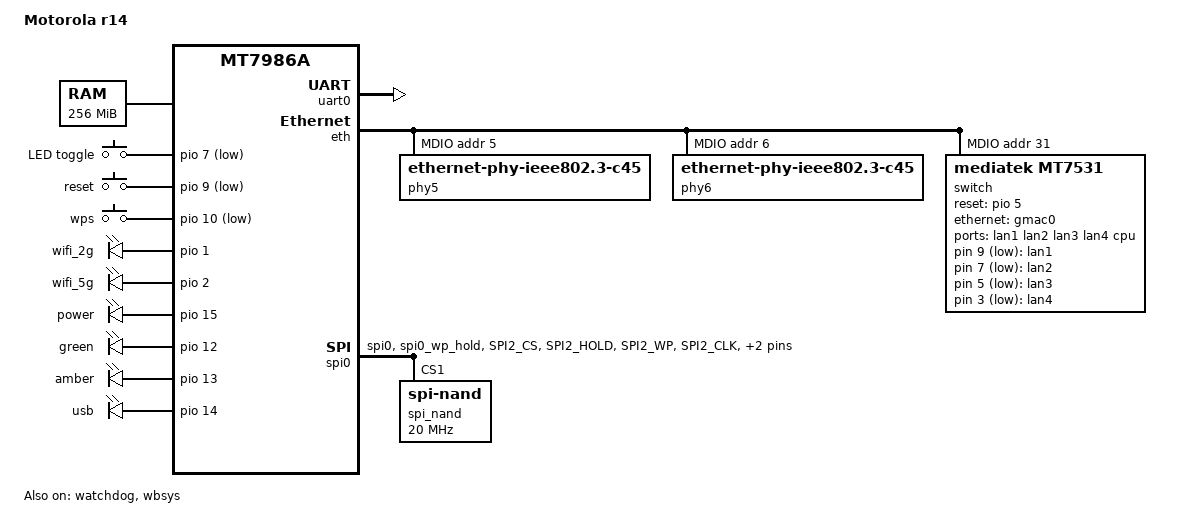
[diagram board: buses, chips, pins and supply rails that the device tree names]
/dts-v1/;
#include "mt7986a.dtsi"
#include "mt7986a-pinctrl.dtsi"
#include <dt-bindings/gpio/gpio.h>
#include <dt-bindings/input/linux-event-codes.h>
/ {
	model = "Motorola r14";
	compatible = "motorola,r14";

	chosen {
		bootargs = "console=ttyS0,115200n1 loglevel=8  \
				earlycon=uart8250,mmio32,0x11002000";
	};

	memory {
		reg = <0 0x40000000 0 0x10000000>;
	};

	gpio-keys {
		compatible = "gpio-keys";

		led_toggle {
			label = "LED toggle";
			linux,code = <KEY_LIGHTS_TOGGLE>;
			gpios = <&pio 7 GPIO_ACTIVE_LOW>;			
		};

		reset {
			label = "reset";
			linux,code = <KEY_RESTART>;
			gpios = <&pio 9 GPIO_ACTIVE_LOW>;			
		};

		wps {
			label = "wps";
			linux,code = <KEY_WPS_BUTTON>;
			gpios = <&pio 10 GPIO_ACTIVE_LOW>;
		};
	};

	leds {
		compatible = "gpio-leds";

		wifi_2g {
			label = "wifi_2g";
			gpios = <&pio 1 GPIO_ACTIVE_HIGH>;
			default-state = "off";
		};

		wifi_5g {
			label = "wifi_5g";
			gpios = <&pio 2 GPIO_ACTIVE_HIGH>;
			default-state = "off";
		};

		power {
			label = "power";
			gpios = <&pio 15 GPIO_ACTIVE_HIGH>;
			default-state = "on";
		};

		green {
			label = "green";
			gpios = <&pio 12 GPIO_ACTIVE_HIGH>;
			default-state = "off";
		};

		amber {
			label = "amber";
			gpios = <&pio 13 GPIO_ACTIVE_HIGH>;
			default-state = "off";
		};

		usb {
			label = "usb";
			gpios = <&pio 14 GPIO_ACTIVE_HIGH>;
			default-state = "off";
		};

		lan1 {
			label = "lan1";
			gpios = <&switch 9 GPIO_ACTIVE_LOW>;
			default-state = "off";
		};

		lan2 {
			label = "lan2";
			gpios = <&switch 7 GPIO_ACTIVE_LOW>;
			default-state = "off";
		};

		lan3 {
			label = "lan3";
			gpios = <&switch 5 GPIO_ACTIVE_LOW>;
			default-state = "off";
		};

		lan4 {
			label = "lan4";
			gpios = <&switch 3 GPIO_ACTIVE_LOW>;
			default-state = "off";
		};
        };


	nmbm_spim_nand {
		compatible = "generic,nmbm";

		#address-cells = <1>;
		#size-cells = <1>;

		lower-mtd-device = <&spi_nand>;
		forced-create;

		partitions {
			compatible = "fixed-partitions";
			#address-cells = <1>;
			#size-cells = <1>;

			partition@0 {
				label = "BL2";
				reg = <0x00000 0x0100000>;
				read-only;
			};

			partition@100000 {
				label = "u-boot-env";
				reg = <0x0100000 0x0060000>;
			};

			partition@160000 {
				label = "certificates";
				reg = <0x0160000 0x0020000>;
			};

			factory: partition@180000 {
				label = "Factory";
				reg = <0x180000 0x0200000>;
			};

			partition@380000 {
				label = "FIP";
				reg = <0x380000 0x0200000>;
			};

			partition@580000 {
				label = "ubi";
				reg = <0x580000 0x4000000>;
			};
		};
	};
};

&uart0 {
	status = "okay";
};

&watchdog {
	status = "okay";
};

&eth {
	status = "okay";

	gmac0: mac@0 {
		compatible = "mediatek,eth-mac";
		reg = <0>;
		phy-mode = "2500base-x";

		fixed-link {
			speed = <2500>;
			full-duplex;
			pause;
		};
	};

	gmac1: mac@1 {
		compatible = "mediatek,eth-mac";
		reg = <1>;
		phy-mode = "2500base-x";
		phy-handle = <&phy6>;
	};

	mdio: mdio-bus {
		#address-cells = <1>;
		#size-cells = <0>;

		reset-gpios = <&pio 6 1>;
		reset-delay-us = <600>;

		phy5: phy@5 {
			compatible = "ethernet-phy-ieee802.3-c45";
			reg = <5>;
		};

		phy6: phy@6 {
			compatible = "ethernet-phy-ieee802.3-c45";
			reg = <6>;
		};

		switch: switch@0 {
			compatible = "mediatek,mt7531";
			gpio-controller;
			#gpio-cells = <2>;
			reg = <31>;
			reset-gpios = <&pio 5 0>;

			ports {
				#address-cells = <1>;
				#size-cells = <0>;

				port@1 {
					reg = <1>;
					label = "lan1";
				};

				port@2 {
					reg = <2>;
					label = "lan2";
				};

				port@3 {
					reg = <3>;
					label = "lan3";
				};

				port@4 {
					reg = <4>;
					label = "lan4";
				};

				port@6 {
					reg = <6>;
					label = "cpu";
					ethernet = <&gmac0>;
					phy-mode = "2500base-x";

					fixed-link {
						speed = <2500>;
						full-duplex;
						pause;
					};
				};
			};
		};
	};
};

&spi0 {
	pinctrl-names = "default";
	pinctrl-0 = <&spi_flash_pins>;
	cs-gpios = <0>, <0>;
	status = "okay";

	spi_nand: spi_nand@1 {
		#address-cells = <1>;
		#size-cells = <1>;
		compatible = "spi-nand";
		reg = <1>;
		spi-max-frequency = <20000000>;
		spi-tx-buswidth = <4>;
		spi-rx-buswidth = <4>;
	};
};

&wbsys {
	mediatek,mtd-eeprom = <&factory 0x0000>;
	status = "okay";
	pinctrl-names = "default", "dbdc";
	pinctrl-0 = <&wf_2g_5g_pins>;
	pinctrl-1 = <&wf_dbdc_pins>;
	power-limits {
		r0 {
			country = "US";
			txpower-2g {
				r0 {
					channels = <1 1>;
					rates-cck = <39 39 39 39>;
					rates-ofdm = <37 37 37 37 37 37 37 37>;
					rates-mcs =
						<1 35 35 35 35 35 35 35 35 35 35>,
						<1 28 28 28 28 28 28 28 28 28 28>,
						<1 30 31 32 30 20 33 25 23 39 34>,
						<1 24 26 36 28 31 33 23 33 21 25>;
					rates-ru =
						<4 35 35 35 35 35 35 35 35 35 35 42 35>,
						<3 28 28 28 28 28 28 28 28 28 28 28 28>;
					paths-cck = <51 45 42 39>;
					paths-ofdm = <49 43 40 37>;
					paths-ofdm-bf = <0 43 40 37>;
					paths-ru =
						<1 47 41 38 35 41 38 35 38 35 35>,
						<1 40 34 31 28 34 31 28 31 28 28>,
						<1 27 38 20 26 28 20 29 21 36 30>,
						<1 35 39 24 31 25 30 25 29 27 39>,
						<3 47 41 38 35 41 38 35 38 35 35>;
					paths-ru-bf =
						<1 0 41 38 35 43 39 37 41 37 39>,
						<1 0 34 31 28 36 32 30 34 30 32>,
						<1 0 30 23 39 28 21 25 29 28 21>,
						<1 0 34 20 38 32 35 33 37 26 36>,
						<3 47 41 38 35 43 39 37 41 37 39>;
				};
				r1 {
					channels = <2 2>;
					rates-cck = <40 40 40 40>;
					rates-ofdm = <38 38 38 38 38 38 38 38>;
					rates-mcs =
						<1 37 37 37 37 37 37 37 37 37 37>,
						<1 28 28 28 28 28 28 28 28 28 28>,
						<1 30 31 32 30 20 33 25 23 39 34>,
						<1 24 26 36 28 31 33 23 33 21 25>;
					rates-ru =
						<4 37 37 37 37 37 37 37 37 37 37 37 37>,
						<3 28 28 28 28 28 28 28 28 28 28 28 28>;
					paths-cck = <52 46 43 40>;
					paths-ofdm = <50 44 41 38>;
					paths-ofdm-bf = <0 44 41 38>;
					paths-ru =
						<1 49 43 40 37 43 40 37 40 37 37>,
						<1 40 34 31 28 34 31 28 31 28 28>,
						<1 35 34 39 30 24 33 23 23 36 34>,
						<1 37 33 31 20 33 38 29 33 39 37>,
						<3 49 43 40 37 43 40 37 40 37 37>;
					paths-ru-bf =
						<1 0 43 40 37 45 41 39 43 39 41>,
						<1 0 34 31 28 36 32 30 34 30 32>,
						<1 0 29 21 24 33 24 30 22 22 31>,
						<1 0 38 34 33 23 25 39 30 31 32>,
						<3 49 43 40 37 45 41 39 43 39 41>;
				};
				r2 {
					channels = <3 3>;
					rates-cck = <43 43 43 43>;
					rates-ofdm = <40 40 40 40 40 40 40 40>;
					rates-mcs =
						<1 40 40 40 40 40 40 40 40 40 40>,
						<1 28 28 28 28 28 28 28 28 28 28>,
						<1 38 24 33 22 26 36 31 23 39 33>,
						<1 33 34 34 35 22 28 21 35 35 33>;
					rates-ru =
						<4 40 40 40 40 40 40 40 40 40 40 42 40>,
						<3 28 28 28 28 28 28 28 28 28 28 28 28>;
					paths-cck = <55 49 46 43>;
					paths-ofdm = <52 46 43 40>;
					paths-ofdm-bf = <0 46 43 40>;
					paths-ru =
						<1 52 46 43 40 46 43 40 43 40 40>,
						<1 40 34 31 28 34 31 28 31 28 28>,
						<1 30 38 34 37 35 31 39 20 26 23>,
						<1 33 25 35 25 32 27 35 22 29 35>,
						<3 52 46 43 40 46 43 40 43 40 40>;
					paths-ru-bf =
						<1 0 46 43 40 48 44 42 46 42 44>,
						<1 0 34 31 28 36 32 30 34 30 32>,
						<1 0 33 35 25 33 35 25 29 21 37>,
						<1 0 37 35 26 25 26 30 27 35 34>,
						<3 52 46 43 40 48 44 42 46 42 44>;
				};
				r3 {
					channels = <4 4>;
					rates-cck = <43 43 43 43>;
					rates-ofdm = <40 40 40 40 40 40 40 40>;
					rates-mcs =
						<1 40 40 40 40 40 40 40 40 40 40>,
						<1 32 32 32 32 32 32 32 32 32 32>,
						<1 38 23 25 21 27 38 20 23 39 36>,
						<1 23 24 20 26 37 31 29 30 22 36>;
					rates-ru =
						<4 40 40 40 40 40 40 40 40 40 40 42 40>,
						<3 32 32 32 32 32 32 32 32 32 32 32 32>;
					paths-cck = <55 49 46 43>;
					paths-ofdm = <52 46 43 40>;
					paths-ofdm-bf = <0 46 43 40>;
					paths-ru =
						<1 52 46 43 40 46 43 40 43 40 40>,
						<1 44 38 35 32 38 35 32 35 32 32>,
						<1 30 36 23 20 21 20 28 28 26 24>,
						<1 29 26 22 28 21 24 26 21 38 22>,
						<3 52 46 43 40 46 43 40 43 40 40>;
					paths-ru-bf =
						<1 0 46 43 40 48 44 42 46 42 44>,
						<1 0 38 35 32 40 36 34 38 34 36>,
						<1 0 28 37 30 26 20 38 35 21 27>,
						<1 0 39 39 32 25 26 33 32 33 25>,
						<3 52 46 43 40 48 44 42 46 42 44>;
				};
				r4 {
					channels = <5 5>;
					rates-cck = <43 43 43 43>;
					rates-ofdm = <40 40 40 40 40 40 40 40>;
					rates-mcs =
						<1 40 40 40 40 40 40 40 40 40 40>,
						<1 36 36 36 36 36 36 36 36 36 36>,
						<1 21 37 28 38 39 35 30 29 36 24>,
						<1 30 22 37 34 37 32 34 27 27 31>;
					rates-ru =
						<4 40 40 40 40 40 40 40 40 40 40 42 40>,
						<3 36 36 36 36 36 36 36 36 36 36 36 36>;
					paths-cck = <55 49 46 43>;
					paths-ofdm = <52 46 43 40>;
					paths-ofdm-bf = <0 46 43 40>;
					paths-ru =
						<1 52 46 43 40 46 43 40 43 40 40>,
						<1 48 42 39 36 42 39 36 39 36 36>,
						<1 25 31 23 25 27 25 26 28 25 34>,
						<1 29 38 27 22 37 25 33 35 34 31>,
						<3 52 46 43 40 46 43 40 43 40 40>;
					paths-ru-bf =
						<1 0 46 43 40 48 44 42 46 42 44>,
						<1 0 42 39 36 44 40 38 42 38 40>,
						<1 0 37 29 36 27 25 25 28 30 31>,
						<1 0 23 26 34 34 37 37 23 23 38>,
						<3 52 46 43 40 48 44 42 46 42 44>;
				};
				r5 {
					channels = <6 6>;
					rates-cck = <43 43 43 43>;
					rates-ofdm = <40 40 40 40 40 40 40 40>;
					rates-mcs =
						<1 40 40 40 40 40 40 40 40 40 40>,
						<1 36 36 36 36 36 36 36 36 36 36>,
						<1 33 39 30 36 33 37 38 39 38 35>,
						<1 29 23 22 36 23 21 28 35 36 33>;
					rates-ru =
						<4 40 40 40 40 40 40 40 40 40 40 42 40>,
						<3 36 36 36 36 36 36 36 36 36 36 36 36>;
					paths-cck = <55 49 46 43>;
					paths-ofdm = <52 46 43 40>;
					paths-ofdm-bf = <0 46 43 40>;
					paths-ru =
						<1 52 46 43 40 46 43 40 43 40 40>,
						<1 48 42 39 36 42 39 36 39 36 36>,
						<1 39 28 27 38 36 28 38 23 25 30>,
						<1 30 37 27 24 34 33 39 29 29 24>,
						<3 52 46 43 40 46 43 40 43 40 40>;
					paths-ru-bf =
						<1 0 46 43 40 48 44 42 46 42 44>,
						<1 0 42 39 36 44 40 38 42 38 40>,
						<1 0 33 24 27 27 36 22 26 27 38>,
						<1 0 20 30 32 26 39 36 28 38 34>,
						<3 52 46 43 40 48 44 42 46 42 44>;
				};
				r6 {
					channels = <7 7>;
					rates-cck = <43 43 43 43>;
					rates-ofdm = <40 40 40 40 40 40 40 40>;
					rates-mcs =
						<1 40 40 40 40 40 40 40 40 40 40>,
						<1 36 36 36 36 36 36 36 36 36 36>,
						<1 22 29 34 29 20 28 37 32 28 38>,
						<1 31 23 31 36 25 21 23 23 23 36>;
					rates-ru =
						<4 40 40 40 40 40 40 40 40 40 40 42 40>,
						<3 36 36 36 36 36 36 36 36 36 36 36 36>;
					paths-cck = <55 49 46 43>;
					paths-ofdm = <52 46 43 40>;
					paths-ofdm-bf = <0 46 43 40>;
					paths-ru =
						<1 52 46 43 40 46 43 40 43 40 40>,
						<1 48 42 39 36 42 39 36 39 36 36>,
						<1 24 26 29 29 32 34 26 29 21 37>,
						<1 27 33 25 22 35 20 37 32 30 37>,
						<3 52 46 43 40 46 43 40 43 40 40>;
					paths-ru-bf =
						<1 0 46 43 40 48 44 42 46 42 44>,
						<1 0 42 39 36 44 40 38 42 38 40>,
						<1 0 26 24 27 31 28 22 31 23 32>,
						<1 0 21 33 37 38 34 25 36 39 27>,
						<3 52 46 43 40 48 44 42 46 42 44>;
				};
				r7 {
					channels = <8 8>;
					rates-cck = <43 43 43 43>;
					rates-ofdm = <40 40 40 40 40 40 40 40>;
					rates-mcs =
						<1 40 40 40 40 40 40 40 40 40 40>,
						<1 31 31 31 31 31 31 31 31 31 31>,
						<1 27 20 34 28 20 20 30 36 31 35>,
						<1 37 20 34 38 35 28 20 32 21 25>;
					rates-ru =
						<4 40 40 40 40 40 40 40 40 40 40 42 40>,
						<3 31 31 31 31 31 31 31 31 31 31 31 31>;
					paths-cck = <55 49 46 43>;
					paths-ofdm = <52 46 43 40>;
					paths-ofdm-bf = <0 46 43 40>;
					paths-ru =
						<1 52 46 43 40 46 43 40 43 40 40>,
						<1 43 37 34 31 37 34 31 34 31 31>,
						<1 32 29 31 34 25 30 25 26 36 31>,
						<1 21 33 36 36 36 32 27 31 38 26>,
						<3 52 46 43 40 46 43 40 43 40 40>;
					paths-ru-bf =
						<1 0 46 43 40 48 44 42 46 42 44>,
						<1 0 37 34 31 39 35 33 37 33 35>,
						<1 0 24 29 21 27 21 25 39 35 21>,
						<1 0 36 38 38 32 30 32 39 28 34>,
						<3 52 46 43 40 48 44 42 46 42 44>;
				};
				r8 {
					channels = <9 9>;
					rates-cck = <43 43 43 43>;
					rates-ofdm = <40 40 40 40 40 40 40 40>;
					rates-mcs =
						<1 40 40 40 40 40 40 40 40 40 40>,
						<1 30 30 30 30 30 30 30 30 30 30>,
						<1 25 25 27 35 32 35 20 30 32 37>,
						<1 36 34 38 30 35 39 36 33 20 25>;
					rates-ru =
						<4 40 40 40 40 40 40 40 40 40 40 42 40>,
						<3 30 30 30 30 30 30 30 30 30 30 30 30>;
					paths-cck = <55 49 46 43>;
					paths-ofdm = <52 46 43 40>;
					paths-ofdm-bf = <0 46 43 40>;
					paths-ru =
						<1 52 46 43 40 46 43 40 43 40 40>,
						<1 42 36 33 30 36 33 30 33 30 30>,
						<1 24 27 27 22 25 33 24 32 23 21>,
						<1 33 22 27 35 34 30 21 25 20 35>,
						<3 52 46 43 40 46 43 40 43 40 40>;
					paths-ru-bf =
						<1 0 46 43 40 48 44 42 46 42 44>,
						<1 0 36 33 30 38 34 32 36 32 34>,
						<1 0 24 25 31 20 30 28 34 29 22>,
						<1 0 30 22 26 33 29 37 39 32 37>,
						<3 52 46 43 40 48 44 42 46 42 44>;
				};
				r9 {
					channels = <10 10>;
					rates-cck = <43 43 43 43>;
					rates-ofdm = <40 40 40 40 40 40 40 40>;
					rates-mcs =
						<1 40 40 40 40 40 40 40 40 40 40>,
						<1 30 30 30 30 30 30 30 30 30 30>,
						<1 31 39 34 29 38 29 38 35 24 20>,
						<1 36 34 25 32 32 28 39 25 35 24>;
					rates-ru =
						<4 40 40 40 40 40 40 40 40 40 40 42 40>,
						<3 30 30 30 30 30 30 30 30 30 30 30 30>;
					paths-cck = <55 49 46 43>;
					paths-ofdm = <52 46 43 40>;
					paths-ofdm-bf = <0 46 43 40>;
					paths-ru =
						<1 52 46 43 40 46 43 40 43 40 40>,
						<1 42 36 33 30 36 33 30 33 30 30>,
						<1 27 21 34 30 22 38 30 22 32 38>,
						<1 30 33 34 33 32 24 39 28 39 35>,
						<3 52 46 43 40 46 43 40 43 40 40>;
					paths-ru-bf =
						<1 0 46 43 40 48 44 42 46 42 44>,
						<1 0 36 33 30 38 34 32 36 32 34>,
						<1 0 35 30 38 21 38 23 21 35 28>,
						<1 0 36 35 21 30 38 23 32 33 31>,
						<3 52 46 43 40 48 44 42 46 42 44>;
				};
				r10 {
					channels = <11 11>;
					rates-cck = <37 37 37 37>;
					rates-ofdm = <36 36 36 36 36 36 36 36>;
					rates-mcs =
						<1 36 36 36 36 36 36 36 36 36 36>,
						<1 30 30 30 30 30 30 30 30 30 30>,
						<1 23 26 33 31 26 21 38 34 39 20>,
						<1 29 30 22 31 34 33 28 34 24 20>;
					rates-ru =
						<4 36 36 36 36 36 36 36 36 36 36 42 36>,
						<3 30 30 30 30 30 30 30 30 30 30 30 30>;
					paths-cck = <49 43 40 37>;
					paths-ofdm = <48 42 39 36>;
					paths-ofdm-bf = <0 42 39 36>;
					paths-ru =
						<1 48 42 39 36 42 39 36 39 36 36>,
						<1 42 36 33 30 36 33 30 33 30 30>,
						<1 26 38 39 25 37 26 32 38 36 24>,
						<1 23 36 27 26 29 36 28 31 36 37>,
						<3 48 42 39 36 42 39 36 39 36 36>;
					paths-ru-bf =
						<1 0 42 39 36 44 40 38 42 38 40>,
						<1 0 36 33 30 38 34 32 36 32 34>,
						<1 0 35 23 38 35 37 27 37 26 22>,
						<1 0 24 25 36 38 30 20 27 22 29>,
						<3 48 42 39 36 44 40 38 42 38 40>;
				};
				r11 {
					channels = <12 12>;
					rates-cck = <37 37 37 37>;
					rates-ofdm = <36 36 36 36 36 36 36 36>;
					rates-mcs =
						<1 36 36 36 36 36 36 36 36 36 36>,
						<1 30 30 30 30 30 30 30 30 30 30>,
						<1 20 36 37 24 24 29 34 27 31 24>,
						<1 29 22 21 38 24 25 31 23 20 21>;
					rates-ru =
						<4 36 36 36 36 36 36 36 36 36 36 42 36>,
						<3 30 30 30 30 30 30 30 30 30 30 30 30>;
					paths-cck = <49 43 40 37>;
					paths-ofdm = <48 42 39 36>;
					paths-ofdm-bf = <0 42 39 36>;
					paths-ru =
						<1 48 42 39 36 42 39 36 39 36 36>,
						<1 42 36 33 30 36 33 30 33 30 30>,
						<1 25 23 35 29 35 20 23 39 36 24>,
						<1 34 21 30 34 24 24 24 32 23 31>,
						<3 48 42 39 36 42 39 36 39 36 36>;
					paths-ru-bf =
						<1 0 42 39 36 44 40 38 42 38 40>,
						<1 0 36 33 30 38 34 32 36 32 34>,
						<1 0 25 25 20 21 25 29 37 29 22>,
						<1 0 29 37 25 37 35 31 30 39 39>,
						<3 48 42 39 36 44 40 38 42 38 40>;
				};
				r12 {
					channels = <13 13>;
					rates-cck = <37 37 37 37>;
					rates-ofdm = <36 36 36 36 36 36 36 36>;
					rates-mcs =
						<1 36 36 36 36 36 36 36 36 36 36>,
						<1 30 30 30 30 30 30 30 30 30 30>,
						<1 29 24 37 23 38 36 39 32 35 33>,
						<1 21 26 33 29 27 28 34 36 23 32>;
					rates-ru =
						<4 36 36 36 36 36 36 36 36 36 36 42 36>,
						<3 30 30 30 30 30 30 30 30 30 30 30 30>;
					paths-cck = <49 43 40 37>;
					paths-ofdm = <48 42 39 36>;
					paths-ofdm-bf = <0 42 39 36>;
					paths-ru =
						<1 48 42 39 36 42 39 36 39 36 36>,
						<1 42 36 33 30 36 33 30 33 30 30>,
						<1 28 23 27 25 39 20 23 27 36 30>,
						<1 25 23 34 26 37 26 32 37 36 31>,
						<3 48 42 39 36 42 39 36 39 36 36>;
					paths-ru-bf =
						<1 0 42 39 36 44 40 38 42 38 40>,
						<1 0 36 33 30 38 34 32 36 32 34>,
						<1 0 31 32 31 34 33 27 36 22 20>,
						<1 0 32 25 23 39 20 28 37 21 32>,
						<3 48 42 39 36 44 40 38 42 38 40>;
				};
				r13 {
					channels = <14 14>;
					rates-cck = <37 37 37 37>;
					rates-ofdm = <36 36 36 36 36 36 36 36>;
					rates-mcs =
						<1 36 36 36 36 36 36 36 36 36 36>,
						<1 30 30 30 30 30 30 30 30 30 30>,
						<1 38 29 37 27 28 24 32 37 33 22>,
						<1 31 37 23 28 23 35 21 22 20 34>;
					rates-ru =
						<4 36 36 36 36 36 36 36 36 36 36 42 36>,
						<3 30 30 30 30 30 30 30 30 30 30 30 30>;
					paths-cck = <49 43 40 37>;
					paths-ofdm = <48 42 39 36>;
					paths-ofdm-bf = <0 42 39 36>;
					paths-ru =
						<1 48 42 39 36 42 39 36 39 36 36>,
						<1 42 36 33 30 36 33 30 33 30 30>,
						<1 26 36 26 37 26 20 36 21 30 30>,
						<1 24 33 33 27 25 27 29 39 37 30>,
						<3 48 42 39 36 42 39 36 39 36 36>;
					paths-ru-bf =
						<1 0 42 39 36 44 40 38 42 38 40>,
						<1 0 36 33 30 38 34 32 36 32 34>,
						<1 0 36 24 22 27 32 29 36 36 37>,
						<1 0 33 29 29 36 32 29 36 25 39>,
						<3 48 42 39 36 44 40 38 42 38 40>;
				};
			};
			txpower-5g {
				r0 {
					channels =
						<1 1>,
						<61 61>,
						<121 121>,
						<181 181>;
					rates-cck = <22 26 24 30>;
					rates-ofdm = <24 26 28 32 36 22 24 22>;
					rates-mcs = <4 24 26 28 32 36 22 24 22 26 28>;
					rates-ru =
						<4 24 26 28 32 36 22 24 22 26 28 32 36>,
						<1 22 24 26 28 30 32 34 36 38 24 30 26>,
						<1 26 30 24 38 36 34 32 30 28 26 24 22>,
						<1 20 22 24 30 36 22 32 34 22 24 26 28>;
					paths-cck = <30 24 34 21>;
					paths-ofdm = <20 26 24 28>;
					paths-ofdm-bf = <0 26 24 39>;
					paths-ru =
						<1 24 26 28 30 32 22 26 36 24 22>,
						<1 28 32 36 22 24 22 26 28 32 22>,
						<1 24 22 24 26 28 32 36 22 24 22>,
						<1 31 22 24 26 28 32 36 22 24 22>,
						<3 24 26 28 30 32 22 26 36 24 22>;
					paths-ru-bf =
						<1 0 24 26 28 32 36 22 24 22 26>,
						<1 0 36 24 22 24 26 28 32 36 22>,
						<1 0 24 26 28 32 36 22 24 35 34>,
						<1 0 24 26 28 32 24 26 28 32 36>,
						<3 24 26 28 32 36 22 24 22 26 22>;
				};
				r1 {
					channels =
						<5 5>,
						<65 65>,
						<125 125>,
						<185 185>;
					rates-cck = <26 28 34 22>;
					rates-ofdm = <22 30 24 38 20 16 30 36>;
					rates-mcs = <4 22 30 24 38 20 16 30 36 30 24>;
					rates-ru =
						<4 22 30 24 38 20 16 30 36 30 24 38 20>,
						<1 20 28 22 36 32 18 28 34 26 22 36 26>,
						<1 26 36 22 26 34 28 18 32 36 22 28 20>,
						<1 30 32 22 36 24 26 34 22 36 24 26 38>;
					paths-cck = <22 34 24 24>;
					paths-ofdm = <22 30 22 34>;
					paths-ofdm-bf = <0 30 22 22>;
					paths-ru =
						<1 22 30 24 36 32 24 26 20 36 30>,
						<1 24 38 20 16 30 36 30 24 38 24>,
						<1 30 30 22 30 24 38 20 16 30 30>,
						<1 22 30 22 30 24 38 20 16 30 30>,
						<3 22 30 24 36 32 24 26 20 36 30>;
					paths-ru-bf =
						<1 0 22 30 24 38 20 16 30 36 30>,
						<1 0 20 36 30 22 30 24 38 20 16>,
						<1 0 22 30 24 38 20 16 30 23 35>,
						<1 0 22 30 24 38 22 30 24 38 20>,
						<3 22 30 24 38 20 16 30 36 30 16>;
				};
				r2 {
					channels = <8 8>;
					rates-cck = <29 29 38 36>;
					rates-ofdm = <38 38 38 38 38 38 38 38>;
					rates-mcs =
						<1 39 39 39 39 39 39 39 39 39 39>,
						<1 30 30 30 30 30 30 30 30 30 30>,
						<1 22 22 22 22 22 22 22 22 22 22>,
						<1 20 20 20 20 20 20 20 20 20 20>;
					rates-ru =
						<4 39 39 39 39 39 39 39 39 39 39 39 39>,
						<1 30 30 30 30 30 30 30 30 30 30 30 30>,
						<1 22 22 22 22 22 22 22 22 22 22 22 22>,
						<1 20 20 20 20 20 20 20 20 20 20 20 20>;
					paths-cck = <23 39 37 31>;
					paths-ofdm = <50 44 41 38>;
					paths-ofdm-bf = <0 44 41 38>;
					paths-ru =
						<1 51 45 42 39 45 42 39 42 39 39>,
						<1 42 36 33 30 36 33 30 33 30 30>,
						<1 34 28 25 22 28 25 22 25 22 22>,
						<1 32 26 23 20 26 23 20 23 20 20>,
						<3 51 45 42 39 45 42 39 42 39 39>;
					paths-ru-bf =
						<1 0 45 42 39 47 43 41 45 41 43>,
						<1 0 36 33 30 38 34 32 36 32 34>,
						<1 0 28 25 22 30 26 24 28 24 26>,
						<1 0 26 23 20 28 24 22 26 22 24>,
						<3 51 45 42 39 47 43 41 45 41 43>;
				};
				r3 {
					channels =
						<9 9>,
						<69 69>,
						<129 129>,
						<189 189>;
					rates-cck = <18 30 36 26>;
					rates-ofdm = <36 24 26 30 32 34 22 20>;
					rates-mcs = <4 36 24 26 30 32 34 22 20 24 26>;
					rates-ru =
						<4 36 24 26 30 32 34 22 20 24 26 30 32>,
						<1 34 22 28 28 30 32 22 26 28 32 34 36>,
						<1 36 34 32 28 26 22 32 30 28 28 22 34>,
						<1 22 36 22 26 24 22 30 22 26 30 32 28>;
					paths-cck = <28 21 20 36>;
					paths-ofdm = <26 24 32 22>;
					paths-ofdm-bf = <0 24 32 34>;
					paths-ru =
						<1 26 32 34 24 22 22 26 22 30 28>,
						<1 26 30 32 34 22 20 24 26 30 22>,
						<1 22 28 36 24 26 30 32 34 22 28>,
						<1 29 28 36 24 26 30 32 34 22 28>,
						<3 26 32 34 24 22 22 26 22 30 28>;
					paths-ru-bf =
						<1 0 36 24 26 30 32 34 22 20 24>,
						<1 0 22 30 28 36 24 26 30 32 34>,
						<1 0 36 24 26 30 32 34 22 27 37>,
						<1 0 36 24 26 30 36 24 26 30 32>,
						<3 36 24 26 30 32 34 22 20 24 34>;
				};
				r4 {
					channels = <12 12>;
					rates-cck = <35 29 29 35>;
					rates-ofdm = <38 38 38 38 38 38 38 38>;
					rates-mcs =
						<1 39 39 39 39 39 39 39 39 39 39>,
						<1 30 30 30 30 30 30 30 30 30 30>,
						<1 22 22 22 22 22 22 22 22 22 22>,
						<1 20 20 20 20 20 20 20 20 20 20>;
					rates-ru =
						<4 39 39 39 39 39 39 39 39 39 39 39 39>,
						<1 30 30 30 30 30 30 30 30 30 30 30 30>,
						<1 22 22 22 22 22 22 22 22 22 22 22 22>,
						<1 20 20 20 20 20 20 20 20 20 20 20 20>;
					paths-cck = <31 27 33 27>;
					paths-ofdm = <50 44 41 38>;
					paths-ofdm-bf = <0 44 41 38>;
					paths-ru =
						<1 51 45 42 39 45 42 39 42 39 39>,
						<1 42 36 33 30 36 33 30 33 30 30>,
						<1 34 28 25 22 28 25 22 25 22 22>,
						<1 32 26 23 20 26 23 20 23 20 20>,
						<3 51 45 42 39 45 42 39 42 39 39>;
					paths-ru-bf =
						<1 0 45 42 39 47 43 41 45 41 43>,
						<1 0 36 33 30 38 34 32 36 32 34>,
						<1 0 28 25 22 30 26 24 28 24 26>,
						<1 0 26 23 20 28 24 22 26 22 24>,
						<3 51 45 42 39 47 43 41 45 41 43>;
				};
				r5 {
					channels =
						<13 13>,
						<73 73>,
						<133 133>;
					rates-cck = <16 18 20 22>;
					rates-ofdm = <24 26 28 32 36 22 24 22>;
					rates-mcs = <4 24 26 28 32 36 22 24 22 26 28>;
					rates-ru =
						<4 24 26 28 32 36 22 24 22 26 28 32 36>,
						<1 22 24 26 28 30 32 34 36 38 24 30 26>,
						<1 26 30 24 38 36 34 32 30 28 26 24 22>,
						<1 20 22 24 30 36 22 32 34 22 24 26 28>;
					paths-cck = <20 28 35 31>;
					paths-ofdm = <20 36 34 24>;
					paths-ofdm-bf = <0 36 34 30>;
					paths-ru =
						<1 24 26 28 30 32 22 26 36 24 22>,
						<1 28 32 36 22 24 22 26 28 32 22>,
						<1 24 22 24 26 28 32 36 22 24 22>,
						<1 30 22 24 26 28 32 36 22 24 22>,
						<3 24 26 28 30 32 22 26 36 24 22>;
					paths-ru-bf =
						<1 0 24 26 28 32 36 22 24 22 26>,
						<1 0 36 24 22 24 26 28 32 36 22>,
						<1 0 24 26 28 32 36 22 24 21 34>,
						<1 0 24 26 28 32 24 26 28 32 36>,
						<3 24 26 28 32 36 22 24 22 26 22>;
				};
				r6 {
					channels = <16 16>;
					rates-cck = <35 25 33 36>;
					rates-ofdm = <38 38 38 38 38 38 38 38>;
					rates-mcs =
						<1 39 39 39 39 39 39 39 39 39 39>,
						<1 30 30 30 30 30 30 30 30 30 30>,
						<1 22 22 22 22 22 22 22 22 22 22>,
						<1 20 20 20 20 20 20 20 20 20 20>;
					rates-ru =
						<4 39 39 39 39 39 39 39 39 39 39 39 39>,
						<1 30 30 30 30 30 30 30 30 30 30 30 30>,
						<1 22 22 22 22 22 22 22 22 22 22 22 22>,
						<1 20 20 20 20 20 20 20 20 20 20 20 20>;
					paths-cck = <23 34 37 26>;
					paths-ofdm = <50 44 41 38>;
					paths-ofdm-bf = <0 44 41 38>;
					paths-ru =
						<1 51 45 42 39 45 42 39 42 39 39>,
						<1 42 36 33 30 36 33 30 33 30 30>,
						<1 34 28 25 22 28 25 22 25 22 22>,
						<1 32 26 23 20 26 23 20 23 20 20>,
						<3 51 45 42 39 45 42 39 42 39 39>;
					paths-ru-bf =
						<1 0 45 42 39 47 43 41 45 41 43>,
						<1 0 36 33 30 38 34 32 36 32 34>,
						<1 0 28 25 22 30 26 24 28 24 26>,
						<1 0 26 23 20 28 24 22 26 22 24>,
						<3 51 45 42 39 47 43 41 45 41 43>;
				};
				r7 {
					channels =
						<17 17>,
						<77 77>,
						<137 137>;
					rates-cck = <26 24 22 30>;
					rates-ofdm = <22 30 24 38 20 16 30 36>;
					rates-mcs = <4 22 30 24 38 20 16 30 36 30 24>;
					rates-ru =
						<4 22 30 24 38 20 16 30 36 30 24 38 20>,
						<1 20 28 22 36 32 18 28 34 26 22 36 26>,
						<1 26 36 22 26 34 28 18 32 36 22 28 20>,
						<1 30 32 22 36 24 26 34 22 36 24 26 38>;
					paths-cck = <28 33 35 26>;
					paths-ofdm = <20 26 24 28>;
					paths-ofdm-bf = <0 26 24 20>;
					paths-ru =
						<1 22 30 24 36 32 24 26 20 36 30>,
						<1 24 38 20 16 30 36 30 24 38 24>,
						<1 30 30 22 30 24 38 20 16 30 30>,
						<1 33 30 22 30 24 38 20 16 30 30>,
						<3 22 30 24 36 32 24 26 20 36 30>;
					paths-ru-bf =
						<1 0 22 30 24 38 20 16 30 36 30>,
						<1 0 20 36 30 22 30 24 38 20 16>,
						<1 0 22 30 24 38 20 16 30 27 36>,
						<1 0 22 30 24 38 22 30 24 38 20>,
						<3 22 30 24 38 20 16 30 36 30 16>;
				};
				r8 {
					channels =
						<21 21>,
						<81 81>,
						<141 141>;
					rates-cck = <22 26 24 30>;
					rates-ofdm = <36 24 26 30 32 34 22 20>;
					rates-mcs = <4 36 24 26 30 32 34 22 20 24 26>;
					rates-ru =
						<4 36 24 26 30 32 34 22 20 24 26 30 32>,
						<1 34 22 28 28 30 32 22 26 28 32 34 36>,
						<1 36 34 32 28 26 22 32 30 28 28 22 34>,
						<1 22 36 22 26 24 22 30 22 26 30 32 28>;
					paths-cck = <24 24 27 38>;
					paths-ofdm = <22 30 22 34>;
					paths-ofdm-bf = <0 30 22 31>;
					paths-ru =
						<1 26 32 34 24 22 22 26 22 30 28>,
						<1 26 30 32 34 22 20 24 26 30 22>,
						<1 22 28 36 24 26 30 32 34 22 28>,
						<1 30 28 36 24 26 30 32 34 22 28>,
						<3 26 32 34 24 22 22 26 22 30 28>;
					paths-ru-bf =
						<1 0 36 24 26 30 32 34 22 20 24>,
						<1 0 22 30 28 36 24 26 30 32 34>,
						<1 0 36 24 26 30 32 34 22 27 35>,
						<1 0 36 24 26 30 36 24 26 30 32>,
						<3 36 24 26 30 32 34 22 20 24 34>;
				};
				r9 {
					channels =
						<25 25>,
						<85 85>,
						<145 145>;
					rates-cck = <26 28 34 22>;
					rates-ofdm = <24 26 28 32 36 22 24 22>;
					rates-mcs = <4 24 26 28 32 36 22 24 22 26 28>;
					rates-ru =
						<4 24 26 28 32 36 22 24 22 26 28 32 36>,
						<1 22 24 26 28 30 32 34 36 38 24 30 26>,
						<1 26 30 24 38 36 34 32 30 28 26 24 22>,
						<1 20 22 24 30 36 22 32 34 22 24 26 28>;
					paths-cck = <34 37 24 35>;
					paths-ofdm = <26 24 32 22>;
					paths-ofdm-bf = <0 24 32 26>;
					paths-ru =
						<1 24 26 28 30 32 22 26 36 24 22>,
						<1 28 32 36 22 24 22 26 28 32 22>,
						<1 24 22 24 26 28 32 36 22 24 22>,
						<1 30 22 24 26 28 32 36 22 24 22>,
						<3 24 26 28 30 32 22 26 36 24 22>;
					paths-ru-bf =
						<1 0 24 26 28 32 36 22 24 22 26>,
						<1 0 36 24 22 24 26 28 32 36 22>,
						<1 0 24 26 28 32 36 22 24 22 21>,
						<1 0 24 26 28 32 24 26 28 32 36>,
						<3 24 26 28 32 36 22 24 22 26 22>;
				};
				r10 {
					channels =
						<29 29>,
						<89 89>,
						<149 149>;
					rates-cck = <18 30 36 26>;
					rates-ofdm = <22 30 24 38 20 16 30 36>;
					rates-mcs = <4 22 30 24 38 20 16 30 36 30 24>;
					rates-ru =
						<4 22 30 24 38 20 16 30 36 30 24 38 20>,
						<1 20 28 22 36 32 18 28 34 26 22 36 26>,
						<1 26 36 22 26 34 28 18 32 36 22 28 20>,
						<1 30 32 22 36 24 26 34 22 36 24 26 38>;
					paths-cck = <30 31 22 37>;
					paths-ofdm = <20 36 34 24>;
					paths-ofdm-bf = <0 36 34 23>;
					paths-ru =
						<1 22 30 24 36 32 24 26 20 36 30>,
						<1 24 38 20 16 30 36 30 24 38 24>,
						<1 30 30 22 30 24 38 20 16 30 30>,
						<1 39 30 22 30 24 38 20 16 30 30>,
						<3 22 30 24 36 32 24 26 20 36 30>;
					paths-ru-bf =
						<1 0 22 30 24 38 20 16 30 36 30>,
						<1 0 20 36 30 22 30 24 38 20 16>,
						<1 0 22 30 24 38 20 16 30 20 34>,
						<1 0 22 30 24 38 22 30 24 38 20>,
						<3 22 30 24 38 20 16 30 36 30 16>;
				};
				r11 {
					channels =
						<33 33>,
						<93 93>,
						<153 153>;
					rates-cck = <16 18 20 22>;
					rates-ofdm = <36 24 26 30 32 34 22 20>;
					rates-mcs = <4 36 24 26 30 32 34 22 20 24 26>;
					rates-ru =
						<4 36 24 26 30 32 34 22 20 24 26 30 32>,
						<1 34 22 28 28 30 32 22 26 28 32 34 36>,
						<1 36 34 32 28 26 22 32 30 28 28 22 34>,
						<1 22 36 22 26 24 22 30 22 26 30 32 28>;
					paths-cck = <29 31 31 29>;
					paths-ofdm = <20 26 24 28>;
					paths-ofdm-bf = <0 26 24 37>;
					paths-ru =
						<1 26 32 34 24 22 22 26 22 30 28>,
						<1 26 30 32 34 22 20 24 26 30 22>,
						<1 22 28 36 24 26 30 32 34 22 28>,
						<1 27 28 36 24 26 30 32 34 22 28>,
						<3 26 32 34 24 22 22 26 22 30 28>;
					paths-ru-bf =
						<1 0 36 24 26 30 32 34 22 20 24>,
						<1 0 22 30 28 36 24 26 30 32 34>,
						<1 0 36 24 26 30 32 34 22 22 38>,
						<1 0 36 24 26 30 36 24 26 30 32>,
						<3 36 24 26 30 32 34 22 20 24 34>;
				};
				r12 {
					channels = <36 36>;
					rates-cck = <27 37 29 34>;
					rates-ofdm = <38 38 38 38 38 38 38 38>;
					rates-mcs =
						<1 39 39 39 39 39 39 39 39 39 39>,
						<1 30 30 30 30 30 30 30 30 30 30>,
						<1 22 22 22 22 22 22 22 22 22 22>,
						<1 20 20 20 20 20 20 20 20 20 20>;
					rates-ru =
						<4 39 39 39 39 39 39 39 39 39 39 39 39>,
						<1 30 30 30 30 30 30 30 30 30 30 30 30>,
						<1 22 22 22 22 22 22 22 22 22 22 22 22>,
						<1 20 20 20 20 20 20 20 20 20 20 20 20>;
					paths-cck = <22 21 28 34>;
					paths-ofdm = <50 44 41 38>;
					paths-ofdm-bf = <0 44 41 38>;
					paths-ru =
						<1 51 45 42 39 45 42 39 42 39 39>,
						<1 42 36 33 30 36 33 30 33 30 30>,
						<1 34 28 25 22 28 25 22 25 22 22>,
						<1 32 26 23 20 26 23 20 23 20 20>,
						<3 51 45 42 39 45 42 39 42 39 39>;
					paths-ru-bf =
						<1 0 45 42 39 47 43 41 45 41 43>,
						<1 0 36 33 30 38 34 32 36 32 34>,
						<1 0 28 25 22 30 26 24 28 24 26>,
						<1 0 26 23 20 28 24 22 26 22 24>,
						<3 51 45 42 39 47 43 41 45 41 43>;
				};
				r13 {
					channels =
						<37 37>,
						<97 97>,
						<157 157>;
					rates-cck = <26 24 22 30>;
					rates-ofdm = <24 26 28 32 36 22 24 22>;
					rates-mcs = <4 24 26 28 32 36 22 24 22 26 28>;
					rates-ru =
						<4 24 26 28 32 36 22 24 22 26 28 32 36>,
						<1 22 24 26 28 30 32 34 36 38 24 30 26>,
						<1 26 30 24 38 36 34 32 30 28 26 24 22>,
						<1 20 22 24 30 36 22 32 34 22 24 26 28>;
					paths-cck = <38 27 31 33>;
					paths-ofdm = <22 30 22 34>;
					paths-ofdm-bf = <0 30 22 32>;
					paths-ru =
						<1 24 26 28 30 32 22 26 36 24 22>,
						<1 28 32 36 22 24 22 26 28 32 22>,
						<1 24 22 24 26 28 32 36 22 24 22>,
						<1 31 22 24 26 28 32 36 22 24 22>,
						<3 24 26 28 30 32 22 26 36 24 22>;
					paths-ru-bf =
						<1 0 24 26 28 32 36 22 24 22 26>,
						<1 0 36 24 22 24 26 28 32 36 22>,
						<1 0 24 26 28 32 36 22 24 30 32>,
						<1 0 24 26 28 32 24 26 28 32 36>,
						<3 24 26 28 32 36 22 24 22 26 22>;
				};
				r14 {
					channels = <40 40>;
					rates-cck = <29 21 31 27>;
					rates-ofdm = <39 39 39 39 39 39 39 39>;
					rates-mcs =
						<1 39 39 39 39 39 39 39 39 39 39>,
						<1 30 30 30 30 30 30 30 30 30 30>,
						<1 22 22 22 22 22 22 22 22 22 22>,
						<1 20 20 20 20 20 20 20 20 20 20>;
					rates-ru =
						<4 39 39 39 39 39 39 39 39 39 39 39 39>,
						<1 30 30 30 30 30 30 30 30 30 30 30 30>,
						<1 22 22 22 22 22 22 22 22 22 22 22 22>,
						<1 20 20 20 20 20 20 20 20 20 20 20 20>;
					paths-cck = <34 26 36 24>;
					paths-ofdm = <51 45 42 39>;
					paths-ofdm-bf = <0 45 42 39>;
					paths-ru =
						<1 51 45 42 39 45 42 39 42 39 39>,
						<1 42 36 33 30 36 33 30 33 30 30>,
						<1 34 28 25 22 28 25 22 25 22 22>,
						<1 32 26 23 20 26 23 20 23 20 20>,
						<3 51 45 42 39 45 42 39 42 39 39>;
					paths-ru-bf =
						<1 0 45 42 39 47 43 41 45 41 43>,
						<1 0 36 33 30 38 34 32 36 32 34>,
						<1 0 28 25 22 30 26 24 28 24 26>,
						<1 0 26 23 20 28 24 22 26 22 24>,
						<3 51 45 42 39 47 43 41 45 41 43>;
				};
				r15 {
					channels =
						<41 41>,
						<101 101>,
						<161 161>;
					rates-cck = <22 26 24 30>;
					rates-ofdm = <22 30 24 38 20 16 30 36>;
					rates-mcs = <4 22 30 24 38 20 16 30 36 30 24>;
					rates-ru =
						<4 22 30 24 38 20 16 30 36 30 24 38 20>,
						<1 20 28 22 36 32 18 28 34 26 22 36 26>,
						<1 26 36 22 26 34 28 18 32 36 22 28 20>,
						<1 30 32 22 36 24 26 34 22 36 24 26 38>;
					paths-cck = <34 28 35 37>;
					paths-ofdm = <26 24 32 22>;
					paths-ofdm-bf = <0 24 32 36>;
					paths-ru =
						<1 22 30 24 36 32 24 26 20 36 30>,
						<1 24 38 20 16 30 36 30 24 38 24>,
						<1 30 30 22 30 24 38 20 16 30 30>,
						<1 34 30 22 30 24 38 20 16 30 30>,
						<3 22 30 24 36 32 24 26 20 36 30>;
					paths-ru-bf =
						<1 0 22 30 24 38 20 16 30 36 30>,
						<1 0 20 36 30 22 30 24 38 20 16>,
						<1 0 22 30 24 38 20 16 30 35 25>,
						<1 0 22 30 24 38 22 30 24 38 20>,
						<3 22 30 24 38 20 16 30 36 30 16>;
				};
				r16 {
					channels = <44 44>;
					rates-cck = <34 36 35 27>;
					rates-ofdm = <39 39 39 39 39 39 39 39>;
					rates-mcs =
						<1 39 39 39 39 39 39 39 39 39 39>,
						<1 37 37 37 37 37 37 37 37 37 37>,
						<1 22 22 22 22 22 22 22 22 22 22>,
						<1 20 20 20 20 20 20 20 20 20 20>;
					rates-ru =
						<4 39 39 39 39 39 39 39 39 39 39 39 39>,
						<1 37 37 37 37 37 37 37 37 37 37 37 37>,
						<1 22 22 22 22 22 22 22 22 22 22 22 22>,
						<1 20 20 20 20 20 20 20 20 20 20 20 20>;
					paths-cck = <25 21 32 38>;
					paths-ofdm = <51 45 42 39>;
					paths-ofdm-bf = <0 45 42 39>;
					paths-ru =
						<1 51 45 42 39 45 42 39 42 39 39>,
						<1 49 43 40 37 43 40 37 40 37 37>,
						<1 34 28 25 22 28 25 22 25 22 22>,
						<1 32 26 23 20 26 23 20 23 20 20>,
						<3 51 45 42 39 45 42 39 42 39 39>;
					paths-ru-bf =
						<1 0 45 42 39 47 43 41 45 41 43>,
						<1 0 43 40 37 45 41 39 43 39 41>,
						<1 0 28 25 22 30 26 24 28 24 26>,
						<1 0 26 23 20 28 24 22 26 22 24>,
						<3 51 45 42 39 47 43 41 45 41 43>;
				};
				r17 {
					channels =
						<45 45>,
						<105 105>,
						<165 165>;
					rates-cck = <26 28 34 22>;
					rates-ofdm = <36 24 26 30 32 34 22 20>;
					rates-mcs = <4 36 24 26 30 32 34 22 20 24 26>;
					rates-ru =
						<4 36 24 26 30 32 34 22 20 24 26 30 32>,
						<1 34 22 28 28 30 32 22 26 28 32 34 36>,
						<1 36 34 32 28 26 22 32 30 28 28 22 34>,
						<1 22 36 22 26 24 22 30 22 26 30 32 28>;
					paths-cck = <29 22 27 38>;
					paths-ofdm = <20 36 34 24>;
					paths-ofdm-bf = <0 36 34 22>;
					paths-ru =
						<1 26 32 34 24 22 22 26 22 30 28>,
						<1 26 30 32 34 22 20 24 26 30 22>,
						<1 22 28 36 24 26 30 32 34 22 28>,
						<1 32 28 36 24 26 30 32 34 22 28>,
						<3 26 32 34 24 22 22 26 22 30 28>;
					paths-ru-bf =
						<1 0 36 24 26 30 32 34 22 20 24>,
						<1 0 22 30 28 36 24 26 30 32 34>,
						<1 0 36 24 26 30 32 34 22 26 32>,
						<1 0 36 24 26 30 36 24 26 30 32>,
						<3 36 24 26 30 32 34 22 20 24 34>;
				};
				r18 {
					channels = <48 48>;
					rates-cck = <29 38 21 23>;
					rates-ofdm = <39 39 39 39 39 39 39 39>;
					rates-mcs =
						<1 39 39 39 39 39 39 39 39 39 39>,
						<1 37 37 37 37 37 37 37 37 37 37>,
						<1 22 22 22 22 22 22 22 22 22 22>,
						<1 20 20 20 20 20 20 20 20 20 20>;
					rates-ru =
						<4 39 39 39 39 39 39 39 39 39 39 39 39>,
						<1 37 37 37 37 37 37 37 37 37 37 37 37>,
						<1 22 22 22 22 22 22 22 22 22 22 22 22>,
						<1 20 20 20 20 20 20 20 20 20 20 20 20>;
					paths-cck = <21 36 32 28>;
					paths-ofdm = <51 45 42 39>;
					paths-ofdm-bf = <0 45 42 39>;
					paths-ru =
						<1 51 45 42 39 45 42 39 42 39 39>,
						<1 49 43 40 37 43 40 37 40 37 37>,
						<1 34 28 25 22 28 25 22 25 22 22>,
						<1 32 26 23 20 26 23 20 23 20 20>,
						<3 51 45 42 39 45 42 39 42 39 39>;
					paths-ru-bf =
						<1 0 45 42 39 47 43 41 45 41 43>,
						<1 0 43 40 37 45 41 39 43 39 41>,
						<1 0 28 25 22 30 26 24 28 24 26>,
						<1 0 26 23 20 28 24 22 26 22 24>,
						<3 51 45 42 39 47 43 41 45 41 43>;
				};
				r19 {
					channels =
						<49 49>,
						<109 109>,
						<169 169>;
					rates-cck = <18 30 36 26>;
					rates-ofdm = <24 26 28 32 36 22 24 22>;
					rates-mcs = <4 24 26 28 32 36 22 24 22 26 28>;
					rates-ru =
						<4 24 26 28 32 36 22 24 22 26 28 32 36>,
						<1 22 24 26 28 30 32 34 36 38 24 30 26>,
						<1 26 30 24 38 36 34 32 30 28 26 24 22>,
						<1 20 22 24 30 36 22 32 34 22 24 26 28>;
					paths-cck = <35 26 35 31>;
					paths-ofdm = <20 26 24 28>;
					paths-ofdm-bf = <0 26 24 25>;
					paths-ru =
						<1 24 26 28 30 32 22 26 36 24 22>,
						<1 28 32 36 22 24 22 26 28 32 22>,
						<2 24 22 24 26 28 32 36 22 24 22>,
						<3 24 26 28 30 32 22 26 36 24 22>;
					paths-ru-bf =
						<1 0 24 26 28 32 36 22 24 22 26>,
						<1 0 36 24 22 24 26 28 32 36 22>,
						<1 0 24 26 28 32 36 22 24 20 23>,
						<1 0 24 26 28 32 24 26 28 32 36>,
						<3 24 26 28 32 36 22 24 22 26 22>;
				};
				r20 {
					channels = <52 52>;
					rates-cck = <37 38 28 38>;
					rates-ofdm = <29 29 29 29 29 29 29 29>;
					rates-mcs =
						<1 28 28 28 28 28 28 28 28 28 28>,
						<1 32 32 32 32 32 32 32 32 32 32>,
						<2 20 20 20 20 20 20 20 20 20 20>;
					rates-ru =
						<4 28 28 28 28 28 28 28 28 28 28 28 28>,
						<1 32 32 32 32 32 32 32 32 32 32 32 32>,
						<2 20 20 20 20 20 20 20 20 20 20 20 20>;
					paths-cck = <27 21 24 25>;
					paths-ofdm = <41 35 32 29>;
					paths-ofdm-bf = <0 35 32 29>;
					paths-ru =
						<1 40 34 31 28 34 31 28 31 28 28>,
						<1 44 38 35 32 38 35 32 35 32 32>,
						<2 32 26 23 20 26 23 20 23 20 20>,
						<3 40 34 31 28 34 31 28 31 28 28>;
					paths-ru-bf =
						<1 0 34 31 28 36 32 30 34 30 32>,
						<1 0 38 35 32 40 36 34 38 34 36>,
						<2 0 26 23 20 28 24 22 26 22 24>,
						<3 40 34 31 28 36 32 30 34 30 32>;
				};
				r21 {
					channels =
						<53 53>,
						<113 113>,
						<173 173>;
					rates-cck = <16 18 20 22>;
					rates-ofdm = <22 30 24 38 20 16 30 36>;
					rates-mcs = <4 22 30 24 38 20 16 30 36 30 24>;
					rates-ru =
						<4 22 30 24 38 20 16 30 36 30 24 38 20>,
						<1 20 28 22 36 32 18 28 34 26 22 36 26>,
						<1 26 36 22 26 34 28 18 32 36 22 28 20>,
						<1 30 32 22 36 24 26 34 22 36 24 26 38>;
					paths-cck = <22 33 29 34>;
					paths-ofdm = <22 30 22 34>;
					paths-ofdm-bf = <0 30 22 26>;
					paths-ru =
						<1 22 30 24 36 32 24 26 20 36 30>,
						<1 24 38 20 16 30 36 30 24 38 24>,
						<1 30 30 22 30 24 38 20 16 30 30>,
						<1 35 30 22 30 24 38 20 16 30 30>,
						<3 22 30 24 36 32 24 26 20 36 30>;
					paths-ru-bf =
						<1 0 22 30 24 38 20 16 30 36 30>,
						<1 0 20 36 30 22 30 24 38 20 16>,
						<1 0 22 30 24 38 20 16 30 35 27>,
						<1 0 22 30 24 38 22 30 24 38 20>,
						<3 22 30 24 38 20 16 30 36 30 16>;
				};
				r22 {
					channels = <56 56>;
					rates-cck = <35 23 22 30>;
					rates-ofdm = <29 29 29 29 29 29 29 29>;
					rates-mcs =
						<1 29 29 29 29 29 29 29 29 29 29>,
						<1 32 32 32 32 32 32 32 32 32 32>,
						<2 20 20 20 20 20 20 20 20 20 20>;
					rates-ru =
						<4 29 29 29 29 29 29 29 29 29 29 29 29>,
						<1 32 32 32 32 32 32 32 32 32 32 32 32>,
						<2 20 20 20 20 20 20 20 20 20 20 20 20>;
					paths-cck = <34 34 33 20>;
					paths-ofdm = <41 35 32 29>;
					paths-ofdm-bf = <0 35 32 29>;
					paths-ru =
						<1 41 35 32 29 35 32 29 32 29 29>,
						<1 44 38 35 32 38 35 32 35 32 32>,
						<2 32 26 23 20 26 23 20 23 20 20>,
						<3 41 35 32 29 35 32 29 32 29 29>;
					paths-ru-bf =
						<1 0 35 32 29 37 33 31 35 31 33>,
						<1 0 38 35 32 40 36 34 38 34 36>,
						<2 0 26 23 20 28 24 22 26 22 24>,
						<3 41 35 32 29 37 33 31 35 31 33>;
				};
				r23 {
					channels =
						<57 57>,
						<117 117>,
						<177 177>;
					rates-cck = <26 24 22 30>;
					rates-ofdm = <36 24 26 30 32 34 22 20>;
					rates-mcs = <4 36 24 26 30 32 34 22 20 24 26>;
					rates-ru =
						<4 36 24 26 30 32 34 22 20 24 26 30 32>,
						<1 34 22 28 28 30 32 22 26 28 32 34 36>,
						<1 36 34 32 28 26 22 32 30 28 28 22 34>,
						<1 22 36 22 26 24 22 30 22 26 30 32 28>;
					paths-cck = <33 38 23 36>;
					paths-ofdm = <26 24 32 22>;
					paths-ofdm-bf = <0 24 32 33>;
					paths-ru =
						<1 26 32 34 24 22 22 26 22 30 28>,
						<1 26 30 32 34 22 20 24 26 30 22>,
						<1 22 28 36 24 26 30 32 34 22 28>,
						<1 28 28 36 24 26 30 32 34 22 28>,
						<3 26 32 34 24 22 22 26 22 30 28>;
					paths-ru-bf =
						<1 0 36 24 26 30 32 34 22 20 24>,
						<1 0 22 30 28 36 24 26 30 32 34>,
						<1 0 36 24 26 30 32 34 22 29 25>,
						<1 0 36 24 26 30 36 24 26 30 32>,
						<3 36 24 26 30 32 34 22 20 24 34>;
				};
				r24 {
					channels = <60 60>;
					rates-cck = <37 24 37 22>;
					rates-ofdm = <29 29 29 29 29 29 29 29>;
					rates-mcs =
						<1 29 29 29 29 29 29 29 29 29 29>,
						<1 32 32 32 32 32 32 32 32 32 32>,
						<2 20 20 20 20 20 20 20 20 20 20>;
					rates-ru =
						<4 29 29 29 29 29 29 29 29 29 29 29 29>,
						<1 32 32 32 32 32 32 32 32 32 32 32 32>,
						<2 20 20 20 20 20 20 20 20 20 20 20 20>;
					paths-cck = <29 31 29 23>;
					paths-ofdm = <41 35 32 29>;
					paths-ofdm-bf = <0 35 32 29>;
					paths-ru =
						<1 41 35 32 29 35 32 29 32 29 29>,
						<1 44 38 35 32 38 35 32 35 32 32>,
						<2 32 26 23 20 26 23 20 23 20 20>,
						<3 41 35 32 29 35 32 29 32 29 29>;
					paths-ru-bf =
						<1 0 35 32 29 37 33 31 35 31 33>,
						<1 0 38 35 32 40 36 34 38 34 36>,
						<2 0 26 23 20 28 24 22 26 22 24>,
						<3 41 35 32 29 37 33 31 35 31 33>;
				};
				r25 {
					channels = <64 64>;
					rates-cck = <29 30 24 29>;
					rates-ofdm = <29 29 29 29 29 29 29 29>;
					rates-mcs =
						<1 29 29 29 29 29 29 29 29 29 29>,
						<1 32 32 32 32 32 32 32 32 32 32>,
						<2 20 20 20 20 20 20 20 20 20 20>;
					rates-ru =
						<4 29 29 29 29 29 29 29 29 29 29 29 29>,
						<1 32 32 32 32 32 32 32 32 32 32 32 32>,
						<2 20 20 20 20 20 20 20 20 20 20 20 20>;
					paths-cck = <35 37 25 36>;
					paths-ofdm = <41 35 32 29>;
					paths-ofdm-bf = <0 35 32 29>;
					paths-ru =
						<1 41 35 32 29 35 32 29 32 29 29>,
						<1 44 38 35 32 38 35 32 35 32 32>,
						<2 32 26 23 20 26 23 20 23 20 20>,
						<3 41 35 32 29 35 32 29 32 29 29>;
					paths-ru-bf =
						<1 0 35 32 29 37 33 31 35 31 33>,
						<1 0 38 35 32 40 36 34 38 34 36>,
						<2 0 26 23 20 28 24 22 26 22 24>,
						<3 41 35 32 29 37 33 31 35 31 33>;
				};
				r26 {
					channels = <68 68>;
					rates-cck = <22 23 27 26>;
					rates-ofdm = <29 29 29 29 29 29 29 29>;
					rates-mcs =
						<1 29 29 29 29 29 29 29 29 29 29>,
						<1 32 32 32 32 32 32 32 32 32 32>,
						<2 20 20 20 20 20 20 20 20 20 20>;
					rates-ru =
						<4 29 29 29 29 29 29 29 29 29 29 29 29>,
						<1 32 32 32 32 32 32 32 32 32 32 32 32>,
						<2 20 20 20 20 20 20 20 20 20 20 20 20>;
					paths-cck = <26 27 39 28>;
					paths-ofdm = <41 35 32 29>;
					paths-ofdm-bf = <0 35 32 29>;
					paths-ru =
						<1 41 35 32 29 35 32 29 32 29 29>,
						<1 44 38 35 32 38 35 32 35 32 32>,
						<2 32 26 23 20 26 23 20 23 20 20>,
						<3 41 35 32 29 35 32 29 32 29 29>;
					paths-ru-bf =
						<1 0 35 32 29 37 33 31 35 31 33>,
						<1 0 38 35 32 40 36 34 38 34 36>,
						<2 0 26 23 20 28 24 22 26 22 24>,
						<3 41 35 32 29 37 33 31 35 31 33>;
				};
				r27 {
					channels = <72 72>;
					rates-cck = <30 36 30 20>;
					rates-ofdm = <29 29 29 29 29 29 29 29>;
					rates-mcs =
						<1 29 29 29 29 29 29 29 29 29 29>,
						<1 32 32 32 32 32 32 32 32 32 32>,
						<2 20 20 20 20 20 20 20 20 20 20>;
					rates-ru =
						<4 29 29 29 29 29 29 29 29 29 29 29 29>,
						<1 32 32 32 32 32 32 32 32 32 32 32 32>,
						<2 20 20 20 20 20 20 20 20 20 20 20 20>;
					paths-cck = <39 36 25 38>;
					paths-ofdm = <41 35 32 29>;
					paths-ofdm-bf = <0 35 32 29>;
					paths-ru =
						<1 41 35 32 29 35 32 29 32 29 29>,
						<1 44 38 35 32 38 35 32 35 32 32>,
						<2 32 26 23 20 26 23 20 23 20 20>,
						<3 41 35 32 29 35 32 29 32 29 29>;
					paths-ru-bf =
						<1 0 35 32 29 37 33 31 35 31 33>,
						<1 0 38 35 32 40 36 34 38 34 36>,
						<2 0 26 23 20 28 24 22 26 22 24>,
						<3 41 35 32 29 37 33 31 35 31 33>;
				};
				r28 {
					channels = <76 76>;
					rates-cck = <20 21 25 32>;
					rates-ofdm = <29 29 29 29 29 29 29 29>;
					rates-mcs =
						<1 29 29 29 29 29 29 29 29 29 29>,
						<1 32 32 32 32 32 32 32 32 32 32>,
						<2 20 20 20 20 20 20 20 20 20 20>;
					rates-ru =
						<4 29 29 29 29 29 29 29 29 29 29 29 29>,
						<1 32 32 32 32 32 32 32 32 32 32 32 32>,
						<2 20 20 20 20 20 20 20 20 20 20 20 20>;
					paths-cck = <32 39 36 24>;
					paths-ofdm = <41 35 32 29>;
					paths-ofdm-bf = <0 35 32 29>;
					paths-ru =
						<1 41 35 32 29 35 32 29 32 29 29>,
						<1 44 38 35 32 38 35 32 35 32 32>,
						<2 32 26 23 20 26 23 20 23 20 20>,
						<3 41 35 32 29 35 32 29 32 29 29>;
					paths-ru-bf =
						<1 0 35 32 29 37 33 31 35 31 33>,
						<1 0 38 35 32 40 36 34 38 34 36>,
						<2 0 26 23 20 28 24 22 26 22 24>,
						<3 41 35 32 29 37 33 31 35 31 33>;
				};
				r29 {
					channels = <80 80>;
					rates-cck = <35 24 32 34>;
					rates-ofdm = <29 29 29 29 29 29 29 29>;
					rates-mcs =
						<1 29 29 29 29 29 29 29 29 29 29>,
						<1 32 32 32 32 32 32 32 32 32 32>,
						<2 20 20 20 20 20 20 20 20 20 20>;
					rates-ru =
						<4 29 29 29 29 29 29 29 29 29 29 29 29>,
						<1 32 32 32 32 32 32 32 32 32 32 32 32>,
						<2 20 20 20 20 20 20 20 20 20 20 20 20>;
					paths-cck = <23 23 32 20>;
					paths-ofdm = <41 35 32 29>;
					paths-ofdm-bf = <0 35 32 29>;
					paths-ru =
						<1 41 35 32 29 35 32 29 32 29 29>,
						<1 44 38 35 32 38 35 32 35 32 32>,
						<2 32 26 23 20 26 23 20 23 20 20>,
						<3 41 35 32 29 35 32 29 32 29 29>;
					paths-ru-bf =
						<1 0 35 32 29 37 33 31 35 31 33>,
						<1 0 38 35 32 40 36 34 38 34 36>,
						<2 0 26 23 20 28 24 22 26 22 24>,
						<3 41 35 32 29 37 33 31 35 31 33>;
				};
				r30 {
					channels = <84 84>;
					rates-cck = <32 33 24 30>;
					rates-ofdm = <29 29 29 29 29 29 29 29>;
					rates-mcs =
						<1 29 29 29 29 29 29 29 29 29 29>,
						<1 32 32 32 32 32 32 32 32 32 32>,
						<2 20 20 20 20 20 20 20 20 20 20>;
					rates-ru =
						<4 29 29 29 29 29 29 29 29 29 29 29 29>,
						<1 32 32 32 32 32 32 32 32 32 32 32 32>,
						<2 20 20 20 20 20 20 20 20 20 20 20 20>;
					paths-cck = <33 29 21 21>;
					paths-ofdm = <41 35 32 29>;
					paths-ofdm-bf = <0 35 32 29>;
					paths-ru =
						<1 41 35 32 29 35 32 29 32 29 29>,
						<1 44 38 35 32 38 35 32 35 32 32>,
						<2 32 26 23 20 26 23 20 23 20 20>,
						<3 41 35 32 29 35 32 29 32 29 29>;
					paths-ru-bf =
						<1 0 35 32 29 37 33 31 35 31 33>,
						<1 0 38 35 32 40 36 34 38 34 36>,
						<2 0 26 23 20 28 24 22 26 22 24>,
						<3 41 35 32 29 37 33 31 35 31 33>;
				};
				r31 {
					channels = <88 88>;
					rates-cck = <36 26 23 27>;
					rates-ofdm = <29 29 29 29 29 29 29 29>;
					rates-mcs =
						<1 29 29 29 29 29 29 29 29 29 29>,
						<1 32 32 32 32 32 32 32 32 32 32>,
						<2 20 20 20 20 20 20 20 20 20 20>;
					rates-ru =
						<4 29 29 29 29 29 29 29 29 29 29 29 29>,
						<1 32 32 32 32 32 32 32 32 32 32 32 32>,
						<2 20 20 20 20 20 20 20 20 20 20 20 20>;
					paths-cck = <20 27 21 31>;
					paths-ofdm = <41 35 32 29>;
					paths-ofdm-bf = <0 35 32 29>;
					paths-ru =
						<1 41 35 32 29 35 32 29 32 29 29>,
						<1 44 38 35 32 38 35 32 35 32 32>,
						<2 32 26 23 20 26 23 20 23 20 20>,
						<3 41 35 32 29 35 32 29 32 29 29>;
					paths-ru-bf =
						<1 0 35 32 29 37 33 31 35 31 33>,
						<1 0 38 35 32 40 36 34 38 34 36>,
						<2 0 26 23 20 28 24 22 26 22 24>,
						<3 41 35 32 29 37 33 31 35 31 33>;
				};
				r32 {
					channels = <92 92>;
					rates-cck = <22 24 25 31>;
					rates-ofdm = <29 29 29 29 29 29 29 29>;
					rates-mcs =
						<1 29 29 29 29 29 29 29 29 29 29>,
						<1 32 32 32 32 32 32 32 32 32 32>,
						<2 20 20 20 20 20 20 20 20 20 20>;
					rates-ru =
						<4 29 29 29 29 29 29 29 29 29 29 29 29>,
						<1 32 32 32 32 32 32 32 32 32 32 32 32>,
						<2 20 20 20 20 20 20 20 20 20 20 20 20>;
					paths-cck = <31 29 26 23>;
					paths-ofdm = <41 35 32 29>;
					paths-ofdm-bf = <0 35 32 29>;
					paths-ru =
						<1 41 35 32 29 35 32 29 32 29 29>,
						<1 44 38 35 32 38 35 32 35 32 32>,
						<2 32 26 23 20 26 23 20 23 20 20>,
						<3 41 35 32 29 35 32 29 32 29 29>;
					paths-ru-bf =
						<1 0 35 32 29 37 33 31 35 31 33>,
						<1 0 38 35 32 40 36 34 38 34 36>,
						<2 0 26 23 20 28 24 22 26 22 24>,
						<3 41 35 32 29 37 33 31 35 31 33>;
				};
				r33 {
					channels = <96 96>;
					rates-cck = <34 21 32 20>;
					rates-ofdm = <29 29 29 29 29 29 29 29>;
					rates-mcs =
						<1 29 29 29 29 29 29 29 29 29 29>,
						<1 32 32 32 32 32 32 32 32 32 32>,
						<2 20 20 20 20 20 20 20 20 20 20>;
					rates-ru =
						<4 29 29 29 29 29 29 29 29 29 29 29 29>,
						<1 32 32 32 32 32 32 32 32 32 32 32 32>,
						<2 20 20 20 20 20 20 20 20 20 20 20 20>;
					paths-cck = <26 32 39 28>;
					paths-ofdm = <41 35 32 29>;
					paths-ofdm-bf = <0 35 32 29>;
					paths-ru =
						<1 41 35 32 29 35 32 29 32 29 29>,
						<1 44 38 35 32 38 35 32 35 32 32>,
						<2 32 26 23 20 26 23 20 23 20 20>,
						<3 41 35 32 29 35 32 29 32 29 29>;
					paths-ru-bf =
						<1 0 35 32 29 37 33 31 35 31 33>,
						<1 0 38 35 32 40 36 34 38 34 36>,
						<2 0 26 23 20 28 24 22 26 22 24>,
						<3 41 35 32 29 37 33 31 35 31 33>;
				};
				r34 {
					channels = <100 100>;
					rates-cck = <28 22 35 33>;
					rates-ofdm = <29 29 29 29 29 29 29 29>;
					rates-mcs =
						<1 29 29 29 29 29 29 29 29 29 29>,
						<1 32 32 32 32 32 32 32 32 32 32>,
						<1 24 24 24 24 24 24 24 24 24 24>,
						<1 20 20 20 20 20 20 20 20 20 20>;
					rates-ru =
						<4 29 29 29 29 29 29 29 29 29 29 29 29>,
						<1 32 32 32 32 32 32 32 32 32 32 32 32>,
						<1 24 24 24 24 24 24 24 24 24 24 24 24>,
						<1 20 20 20 20 20 20 20 20 20 20 20 20>;
					paths-cck = <20 24 20 37>;
					paths-ofdm = <41 35 32 29>;
					paths-ofdm-bf = <0 35 32 29>;
					paths-ru =
						<1 41 35 32 29 35 32 29 32 29 29>,
						<1 44 38 35 32 38 35 32 35 32 32>,
						<1 36 30 27 24 30 27 24 27 24 24>,
						<1 32 26 23 20 26 23 20 23 20 20>,
						<3 41 35 32 29 35 32 29 32 29 29>;
					paths-ru-bf =
						<1 0 35 32 29 37 33 31 35 31 33>,
						<1 0 38 35 32 40 36 34 38 34 36>,
						<1 0 30 27 24 32 28 26 30 26 28>,
						<1 0 26 23 20 28 24 22 26 22 24>,
						<3 41 35 32 29 37 33 31 35 31 33>;
				};
				r35 {
					channels = <104 104>;
					rates-cck = <21 31 22 28>;
					rates-ofdm = <29 29 29 29 29 29 29 29>;
					rates-mcs =
						<1 29 29 29 29 29 29 29 29 29 29>,
						<1 32 32 32 32 32 32 32 32 32 32>,
						<1 24 24 24 24 24 24 24 24 24 24>,
						<1 20 20 20 20 20 20 20 20 20 20>;
					rates-ru =
						<4 29 29 29 29 29 29 29 29 29 29 29 29>,
						<1 32 32 32 32 32 32 32 32 32 32 32 32>,
						<1 24 24 24 24 24 24 24 24 24 24 24 24>,
						<1 20 20 20 20 20 20 20 20 20 20 20 20>;
					paths-cck = <28 26 33 26>;
					paths-ofdm = <41 35 32 29>;
					paths-ofdm-bf = <0 35 32 29>;
					paths-ru =
						<1 41 35 32 29 35 32 29 32 29 29>,
						<1 44 38 35 32 38 35 32 35 32 32>,
						<1 36 30 27 24 30 27 24 27 24 24>,
						<1 32 26 23 20 26 23 20 23 20 20>,
						<3 41 35 32 29 35 32 29 32 29 29>;
					paths-ru-bf =
						<1 0 35 32 29 37 33 31 35 31 33>,
						<1 0 38 35 32 40 36 34 38 34 36>,
						<1 0 30 27 24 32 28 26 30 26 28>,
						<1 0 26 23 20 28 24 22 26 22 24>,
						<3 41 35 32 29 37 33 31 35 31 33>;
				};
				r36 {
					channels = <108 108>;
					rates-cck = <31 39 21 35>;
					rates-ofdm = <29 29 29 29 29 29 29 29>;
					rates-mcs =
						<1 29 29 29 29 29 29 29 29 29 29>,
						<1 32 32 32 32 32 32 32 32 32 32>,
						<1 24 24 24 24 24 24 24 24 24 24>,
						<1 20 20 20 20 20 20 20 20 20 20>;
					rates-ru =
						<4 29 29 29 29 29 29 29 29 29 29 29 29>,
						<1 32 32 32 32 32 32 32 32 32 32 32 32>,
						<1 24 24 24 24 24 24 24 24 24 24 24 24>,
						<1 20 20 20 20 20 20 20 20 20 20 20 20>;
					paths-cck = <39 24 33 32>;
					paths-ofdm = <41 35 32 29>;
					paths-ofdm-bf = <0 35 32 29>;
					paths-ru =
						<1 41 35 32 29 35 32 29 32 29 29>,
						<1 44 38 35 32 38 35 32 35 32 32>,
						<1 36 30 27 24 30 27 24 27 24 24>,
						<1 32 26 23 20 26 23 20 23 20 20>,
						<3 41 35 32 29 35 32 29 32 29 29>;
					paths-ru-bf =
						<1 0 35 32 29 37 33 31 35 31 33>,
						<1 0 38 35 32 40 36 34 38 34 36>,
						<1 0 30 27 24 32 28 26 30 26 28>,
						<1 0 26 23 20 28 24 22 26 22 24>,
						<3 41 35 32 29 37 33 31 35 31 33>;
				};
				r37 {
					channels = <112 112>;
					rates-cck = <23 26 25 22>;
					rates-ofdm = <29 29 29 29 29 29 29 29>;
					rates-mcs =
						<1 29 29 29 29 29 29 29 29 29 29>,
						<1 32 32 32 32 32 32 32 32 32 32>,
						<1 24 24 24 24 24 24 24 24 24 24>,
						<1 20 20 20 20 20 20 20 20 20 20>;
					rates-ru =
						<4 29 29 29 29 29 29 29 29 29 29 29 29>,
						<1 32 32 32 32 32 32 32 32 32 32 32 32>,
						<1 24 24 24 24 24 24 24 24 24 24 24 24>,
						<1 20 20 20 20 20 20 20 20 20 20 20 20>;
					paths-cck = <31 21 35 35>;
					paths-ofdm = <41 35 32 29>;
					paths-ofdm-bf = <0 35 32 29>;
					paths-ru =
						<1 41 35 32 29 35 32 29 32 29 29>,
						<1 44 38 35 32 38 35 32 35 32 32>,
						<1 36 30 27 24 30 27 24 27 24 24>,
						<1 32 26 23 20 26 23 20 23 20 20>,
						<3 41 35 32 29 35 32 29 32 29 29>;
					paths-ru-bf =
						<1 0 35 32 29 37 33 31 35 31 33>,
						<1 0 38 35 32 40 36 34 38 34 36>,
						<1 0 30 27 24 32 28 26 30 26 28>,
						<1 0 26 23 20 28 24 22 26 22 24>,
						<3 41 35 32 29 37 33 31 35 31 33>;
				};
				r38 {
					channels = <116 116>;
					rates-cck = <20 39 29 21>;
					rates-ofdm = <29 29 29 29 29 29 29 29>;
					rates-mcs =
						<1 29 29 29 29 29 29 29 29 29 29>,
						<1 32 32 32 32 32 32 32 32 32 32>,
						<1 30 30 30 30 30 30 30 30 30 30>,
						<1 20 20 20 20 20 20 20 20 20 20>;
					rates-ru =
						<4 29 29 29 29 29 29 29 29 29 29 29 29>,
						<1 32 32 32 32 32 32 32 32 32 32 32 32>,
						<1 30 30 30 30 30 30 30 30 30 30 30 30>,
						<1 20 20 20 20 20 20 20 20 20 20 20 20>;
					paths-cck = <30 24 34 21>;
					paths-ofdm = <41 35 32 29>;
					paths-ofdm-bf = <0 35 32 29>;
					paths-ru =
						<1 41 35 32 29 35 32 29 32 29 29>,
						<1 44 38 35 32 38 35 32 35 32 32>,
						<1 42 36 33 30 36 33 30 33 30 30>,
						<1 32 26 23 20 26 23 20 23 20 20>,
						<3 41 35 32 29 35 32 29 32 29 29>;
					paths-ru-bf =
						<1 0 35 32 29 37 33 31 35 31 33>,
						<1 0 38 35 32 40 36 34 38 34 36>,
						<1 0 36 33 30 38 34 32 36 32 34>,
						<1 0 26 23 20 28 24 22 26 22 24>,
						<3 41 35 32 29 37 33 31 35 31 33>;
				};
				r39 {
					channels = <120 120>;
					rates-cck = <38 30 39 37>;
					rates-ofdm = <29 29 29 29 29 29 29 29>;
					rates-mcs =
						<1 29 29 29 29 29 29 29 29 29 29>,
						<1 32 32 32 32 32 32 32 32 32 32>,
						<1 30 30 30 30 30 30 30 30 30 30>,
						<1 20 20 20 20 20 20 20 20 20 20>;
					rates-ru =
						<4 29 29 29 29 29 29 29 29 29 29 29 29>,
						<1 32 32 32 32 32 32 32 32 32 32 32 32>,
						<1 30 30 30 30 30 30 30 30 30 30 30 30>,
						<1 20 20 20 20 20 20 20 20 20 20 20 20>;
					paths-cck = <22 34 24 24>;
					paths-ofdm = <41 35 32 29>;
					paths-ofdm-bf = <0 35 32 29>;
					paths-ru =
						<1 41 35 32 29 35 32 29 32 29 29>,
						<1 44 38 35 32 38 35 32 35 32 32>,
						<1 42 36 33 30 36 33 30 33 30 30>,
						<1 32 26 23 20 26 23 20 23 20 20>,
						<3 41 35 32 29 35 32 29 32 29 29>;
					paths-ru-bf =
						<1 0 35 32 29 37 33 31 35 31 33>,
						<1 0 38 35 32 40 36 34 38 34 36>,
						<1 0 36 33 30 38 34 32 36 32 34>,
						<1 0 26 23 20 28 24 22 26 22 24>,
						<3 41 35 32 29 37 33 31 35 31 33>;
				};
				r40 {
					channels = <124 124>;
					rates-cck = <20 26 23 23>;
					rates-ofdm = <29 29 29 29 29 29 29 29>;
					rates-mcs =
						<1 29 29 29 29 29 29 29 29 29 29>,
						<1 32 32 32 32 32 32 32 32 32 32>,
						<1 30 30 30 30 30 30 30 30 30 30>,
						<1 20 20 20 20 20 20 20 20 20 20>;
					rates-ru =
						<4 29 29 29 29 29 29 29 29 29 29 29 29>,
						<1 32 32 32 32 32 32 32 32 32 32 32 32>,
						<1 30 30 30 30 30 30 30 30 30 30 30 30>,
						<1 20 20 20 20 20 20 20 20 20 20 20 20>;
					paths-cck = <28 21 20 36>;
					paths-ofdm = <41 35 32 29>;
					paths-ofdm-bf = <0 35 32 29>;
					paths-ru =
						<1 41 35 32 29 35 32 29 32 29 29>,
						<1 44 38 35 32 38 35 32 35 32 32>,
						<1 42 36 33 30 36 33 30 33 30 30>,
						<1 32 26 23 20 26 23 20 23 20 20>,
						<3 41 35 32 29 35 32 29 32 29 29>;
					paths-ru-bf =
						<1 0 35 32 29 37 33 31 35 31 33>,
						<1 0 38 35 32 40 36 34 38 34 36>,
						<1 0 36 33 30 38 34 32 36 32 34>,
						<1 0 26 23 20 28 24 22 26 22 24>,
						<3 41 35 32 29 37 33 31 35 31 33>;
				};
				r41 {
					channels = <128 128>;
					rates-cck = <38 37 37 39>;
					rates-ofdm = <29 29 29 29 29 29 29 29>;
					rates-mcs =
						<1 29 29 29 29 29 29 29 29 29 29>,
						<1 32 32 32 32 32 32 32 32 32 32>,
						<1 30 30 30 30 30 30 30 30 30 30>,
						<1 20 20 20 20 20 20 20 20 20 20>;
					rates-ru =
						<4 29 29 29 29 29 29 29 29 29 29 29 29>,
						<1 32 32 32 32 32 32 32 32 32 32 32 32>,
						<1 30 30 30 30 30 30 30 30 30 30 30 30>,
						<1 20 20 20 20 20 20 20 20 20 20 20 20>;
					paths-cck = <20 28 35 31>;
					paths-ofdm = <41 35 32 29>;
					paths-ofdm-bf = <0 35 32 29>;
					paths-ru =
						<1 41 35 32 29 35 32 29 32 29 29>,
						<1 44 38 35 32 38 35 32 35 32 32>,
						<1 42 36 33 30 36 33 30 33 30 30>,
						<1 32 26 23 20 26 23 20 23 20 20>,
						<3 41 35 32 29 35 32 29 32 29 29>;
					paths-ru-bf =
						<1 0 35 32 29 37 33 31 35 31 33>,
						<1 0 38 35 32 40 36 34 38 34 36>,
						<1 0 36 33 30 38 34 32 36 32 34>,
						<1 0 26 23 20 28 24 22 26 22 24>,
						<3 41 35 32 29 37 33 31 35 31 33>;
				};
				r42 {
					channels = <132 132>;
					rates-cck = <29 25 31 21>;
					rates-ofdm = <29 29 29 29 29 29 29 29>;
					rates-mcs =
						<1 29 29 29 29 29 29 29 29 29 29>,
						<1 32 32 32 32 32 32 32 32 32 32>,
						<1 34 34 34 34 34 34 34 34 34 34>,
						<1 20 20 20 20 20 20 20 20 20 20>;
					rates-ru =
						<4 29 29 29 29 29 29 29 29 29 29 29 29>,
						<1 32 32 32 32 32 32 32 32 32 32 32 32>,
						<1 34 34 34 34 34 34 34 34 34 34 34 34>,
						<1 20 20 20 20 20 20 20 20 20 20 20 20>;
					paths-cck = <28 33 35 26>;
					paths-ofdm = <41 35 32 29>;
					paths-ofdm-bf = <0 35 32 29>;
					paths-ru =
						<1 41 35 32 29 35 32 29 32 29 29>,
						<1 44 38 35 32 38 35 32 35 32 32>,
						<1 46 40 37 34 40 37 34 37 34 34>,
						<1 32 26 23 20 26 23 20 23 20 20>,
						<3 41 35 32 29 35 32 29 32 29 29>;
					paths-ru-bf =
						<1 0 35 32 29 37 33 31 35 31 33>,
						<1 0 38 35 32 40 36 34 38 34 36>,
						<1 0 40 37 34 42 38 36 40 36 38>,
						<1 0 26 23 20 28 24 22 26 22 24>,
						<3 41 35 32 29 37 33 31 35 31 33>;
				};
				r43 {
					channels = <136 136>;
					rates-cck = <36 21 21 25>;
					rates-ofdm = <29 29 29 29 29 29 29 29>;
					rates-mcs =
						<1 29 29 29 29 29 29 29 29 29 29>,
						<1 32 32 32 32 32 32 32 32 32 32>,
						<1 34 34 34 34 34 34 34 34 34 34>,
						<1 20 20 20 20 20 20 20 20 20 20>;
					rates-ru =
						<4 29 29 29 29 29 29 29 29 29 29 29 29>,
						<1 32 32 32 32 32 32 32 32 32 32 32 32>,
						<1 34 34 34 34 34 34 34 34 34 34 34 34>,
						<1 20 20 20 20 20 20 20 20 20 20 20 20>;
					paths-cck = <24 24 27 38>;
					paths-ofdm = <41 35 32 29>;
					paths-ofdm-bf = <0 35 32 29>;
					paths-ru =
						<1 41 35 32 29 35 32 29 32 29 29>,
						<1 44 38 35 32 38 35 32 35 32 32>,
						<1 46 40 37 34 40 37 34 37 34 34>,
						<1 32 26 23 20 26 23 20 23 20 20>,
						<3 41 35 32 29 35 32 29 32 29 29>;
					paths-ru-bf =
						<1 0 35 32 29 37 33 31 35 31 33>,
						<1 0 38 35 32 40 36 34 38 34 36>,
						<1 0 40 37 34 42 38 36 40 36 38>,
						<1 0 26 23 20 28 24 22 26 22 24>,
						<3 41 35 32 29 37 33 31 35 31 33>;
				};
				r44 {
					channels = <140 140>;
					rates-cck = <30 31 31 29>;
					rates-ofdm = <29 29 29 29 29 29 29 29>;
					rates-mcs =
						<1 29 29 29 29 29 29 29 29 29 29>,
						<1 32 32 32 32 32 32 32 32 32 32>,
						<1 34 34 34 34 34 34 34 34 34 34>,
						<1 20 20 20 20 20 20 20 20 20 20>;
					rates-ru =
						<4 29 29 29 29 29 29 29 29 29 29 29 29>,
						<1 32 32 32 32 32 32 32 32 32 32 32 32>,
						<1 34 34 34 34 34 34 34 34 34 34 34 34>,
						<1 20 20 20 20 20 20 20 20 20 20 20 20>;
					paths-cck = <34 37 24 35>;
					paths-ofdm = <41 35 32 29>;
					paths-ofdm-bf = <0 35 32 29>;
					paths-ru =
						<1 41 35 32 29 35 32 29 32 29 29>,
						<1 44 38 35 32 38 35 32 35 32 32>,
						<1 46 40 37 34 40 37 34 37 34 34>,
						<1 32 26 23 20 26 23 20 23 20 20>,
						<3 41 35 32 29 35 32 29 32 29 29>;
					paths-ru-bf =
						<1 0 35 32 29 37 33 31 35 31 33>,
						<1 0 38 35 32 40 36 34 38 34 36>,
						<1 0 40 37 34 42 38 36 40 36 38>,
						<1 0 26 23 20 28 24 22 26 22 24>,
						<3 41 35 32 29 37 33 31 35 31 33>;
				};
				r45 {
					channels = <144 144>;
					rates-cck = <27 36 25 33>;
					rates-ofdm = <29 29 29 29 29 29 29 29>;
					rates-mcs =
						<1 29 29 29 29 29 29 29 29 29 29>,
						<1 32 32 32 32 32 32 32 32 32 32>,
						<1 34 34 34 34 34 34 34 34 34 34>,
						<1 20 20 20 20 20 20 20 20 20 20>;
					rates-ru =
						<4 29 29 29 29 29 29 29 29 29 29 29 29>,
						<1 32 32 32 32 32 32 32 32 32 32 32 32>,
						<1 34 34 34 34 34 34 34 34 34 34 34 34>,
						<1 20 20 20 20 20 20 20 20 20 20 20 20>;
					paths-cck = <30 31 22 37>;
					paths-ofdm = <41 35 32 29>;
					paths-ofdm-bf = <0 35 32 29>;
					paths-ru =
						<1 41 35 32 29 35 32 29 32 29 29>,
						<1 44 38 35 32 38 35 32 35 32 32>,
						<1 46 40 37 34 40 37 34 37 34 34>,
						<1 32 26 23 20 26 23 20 23 20 20>,
						<3 41 35 32 29 35 32 29 32 29 29>;
					paths-ru-bf =
						<1 0 35 32 29 37 33 31 35 31 33>,
						<1 0 38 35 32 40 36 34 38 34 36>,
						<1 0 40 37 34 42 38 36 40 36 38>,
						<1 0 26 23 20 28 24 22 26 22 24>,
						<3 41 35 32 29 37 33 31 35 31 33>;
				};
				r46 {
					channels = <184 184>;
					rates-cck = <31 33 38 22>;
					rates-ofdm = <38 38 38 38 38 38 38 38>;
					rates-mcs =
						<1 39 39 39 39 39 39 39 39 39 39>,
						<1 30 30 30 30 30 30 30 30 30 30>,
						<1 22 22 22 22 22 22 22 22 22 22>,
						<1 20 20 20 20 20 20 20 20 20 20>;
					rates-ru =
						<4 39 39 39 39 39 39 39 39 39 39 39 39>,
						<1 30 30 30 30 30 30 30 30 30 30 30 30>,
						<1 22 22 22 22 22 22 22 22 22 22 22 22>,
						<1 20 20 20 20 20 20 20 20 20 20 20 20>;
					paths-cck = <26 31 31 35>;
					paths-ofdm = <50 44 41 38>;
					paths-ofdm-bf = <0 44 41 38>;
					paths-ru =
						<1 51 45 42 39 45 42 39 42 39 39>,
						<1 42 36 33 30 36 33 30 33 30 30>,
						<1 34 28 25 22 28 25 22 25 22 22>,
						<1 32 26 23 20 26 23 20 23 20 20>,
						<3 51 45 42 39 45 42 39 42 39 39>;
					paths-ru-bf =
						<1 0 45 42 39 47 43 41 45 41 43>,
						<1 0 36 33 30 38 34 32 36 32 34>,
						<1 0 28 25 22 30 26 24 28 24 26>,
						<1 0 26 23 20 28 24 22 26 22 24>,
						<3 51 45 42 39 47 43 41 45 41 43>;
				};
				r47 {
					channels = <188 188>;
					rates-cck = <32 21 29 34>;
					rates-ofdm = <38 38 38 38 38 38 38 38>;
					rates-mcs =
						<1 39 39 39 39 39 39 39 39 39 39>,
						<1 30 30 30 30 30 30 30 30 30 30>,
						<1 22 22 22 22 22 22 22 22 22 22>,
						<1 20 20 20 20 20 20 20 20 20 20>;
					rates-ru =
						<4 39 39 39 39 39 39 39 39 39 39 39 39>,
						<1 30 30 30 30 30 30 30 30 30 30 30 30>,
						<1 22 22 22 22 22 22 22 22 22 22 22 22>,
						<1 20 20 20 20 20 20 20 20 20 20 20 20>;
					paths-cck = <36 32 37 34>;
					paths-ofdm = <50 44 41 38>;
					paths-ofdm-bf = <0 44 41 38>;
					paths-ru =
						<1 51 45 42 39 45 42 39 42 39 39>,
						<1 42 36 33 30 36 33 30 33 30 30>,
						<1 34 28 25 22 28 25 22 25 22 22>,
						<1 32 26 23 20 26 23 20 23 20 20>,
						<3 51 45 42 39 45 42 39 42 39 39>;
					paths-ru-bf =
						<1 0 45 42 39 47 43 41 45 41 43>,
						<1 0 36 33 30 38 34 32 36 32 34>,
						<1 0 28 25 22 30 26 24 28 24 26>,
						<1 0 26 23 20 28 24 22 26 22 24>,
						<3 51 45 42 39 47 43 41 45 41 43>;
				};
				r48 {
					channels = <192 192>;
					rates-cck = <39 32 24 29>;
					rates-ofdm = <38 38 38 38 38 38 38 38>;
					rates-mcs =
						<1 39 39 39 39 39 39 39 39 39 39>,
						<1 30 30 30 30 30 30 30 30 30 30>,
						<1 22 22 22 22 22 22 22 22 22 22>,
						<1 20 20 20 20 20 20 20 20 20 20>;
					rates-ru =
						<4 39 39 39 39 39 39 39 39 39 39 39 39>,
						<1 30 30 30 30 30 30 30 30 30 30 30 30>,
						<1 22 22 22 22 22 22 22 22 22 22 22 22>,
						<1 20 20 20 20 20 20 20 20 20 20 20 20>;
					paths-cck = <28 30 37 36>;
					paths-ofdm = <50 44 41 38>;
					paths-ofdm-bf = <0 44 41 38>;
					paths-ru =
						<1 51 45 42 39 45 42 39 42 39 39>,
						<1 42 36 33 30 36 33 30 33 30 30>,
						<1 34 28 25 22 28 25 22 25 22 22>,
						<1 32 26 23 20 26 23 20 23 20 20>,
						<3 51 45 42 39 45 42 39 42 39 39>;
					paths-ru-bf =
						<1 0 45 42 39 47 43 41 45 41 43>,
						<1 0 36 33 30 38 34 32 36 32 34>,
						<1 0 28 25 22 30 26 24 28 24 26>,
						<1 0 26 23 20 28 24 22 26 22 24>,
						<3 51 45 42 39 47 43 41 45 41 43>;
				};
				r49 {
					channels =
						<193 193>,
						<205 205>;
					rates-cck = <16 18 20 22>;
					rates-ofdm = <24 26 28 32 36 22 24 36>;
					rates-mcs = <4 24 26 28 32 36 22 24 36 26 28>;
					rates-ru =
						<4 24 26 28 32 36 22 24 36 26 28 32 36>,
						<1 22 24 26 28 30 32 34 36 38 24 30 26>,
						<1 26 30 24 38 36 34 32 30 28 26 24 22>,
						<1 20 22 24 30 36 22 32 34 22 24 26 28>;
					paths-cck = <33 38 23 36>;
					paths-ofdm = <20 26 24 28>;
					paths-ofdm-bf = <0 26 24 25>;
					paths-ru =
						<1 24 26 28 30 32 22 26 36 24 22>,
						<1 28 32 36 22 24 36 26 28 32 22>,
						<1 24 22 24 26 28 32 36 22 24 22>,
						<1 33 22 24 26 28 32 36 22 24 22>,
						<3 24 26 28 30 32 22 26 36 24 22>;
					paths-ru-bf =
						<1 0 24 26 28 32 36 22 24 36 26>,
						<1 0 36 24 22 24 26 28 32 36 22>,
						<1 0 24 26 28 32 36 22 24 28 22>,
						<1 0 24 26 28 32 24 26 28 32 36>,
						<3 24 26 28 32 36 22 24 36 26 22>;
				};
				r50 {
					channels = <196 196>;
					rates-cck = <27 37 29 24>;
					rates-ofdm = <38 38 38 38 38 38 38 38>;
					rates-mcs =
						<1 39 39 39 39 39 39 39 39 39 39>,
						<1 30 30 30 30 30 30 30 30 30 30>,
						<1 22 22 22 22 22 22 22 22 22 22>,
						<1 20 20 20 20 20 20 20 20 20 20>;
					rates-ru =
						<4 39 39 39 39 39 39 39 39 39 39 39 39>,
						<1 30 30 30 30 30 30 30 30 30 30 30 30>,
						<1 22 22 22 22 22 22 22 22 22 22 22 22>,
						<1 20 20 20 20 20 20 20 20 20 20 20 20>;
					paths-cck = <23 27 23 38>;
					paths-ofdm = <50 44 41 38>;
					paths-ofdm-bf = <0 44 41 38>;
					paths-ru =
						<1 51 45 42 39 45 42 39 42 39 39>,
						<1 42 36 33 30 36 33 30 33 30 30>,
						<1 34 28 25 22 28 25 22 25 22 22>,
						<1 32 26 23 20 26 23 20 23 20 20>,
						<3 51 45 42 39 45 42 39 42 39 39>;
					paths-ru-bf =
						<1 0 45 42 39 47 43 41 45 41 43>,
						<1 0 36 33 30 38 34 32 36 32 34>,
						<1 0 28 25 22 30 26 24 28 24 26>,
						<1 0 26 23 20 28 24 22 26 22 24>,
						<3 51 45 42 39 47 43 41 45 41 43>;
				};
				r51 {
					channels =
						<197 197>,
						<209 209>;
					rates-cck = <26 24 22 30>;
					rates-ofdm = <22 30 24 38 20 16 30 20>;
					rates-mcs = <4 22 30 24 38 20 16 30 20 30 24>;
					rates-ru =
						<4 22 30 24 38 20 16 30 20 30 24 38 20>,
						<1 20 28 22 36 32 18 28 34 26 22 36 26>,
						<1 26 36 22 26 34 28 18 32 36 22 28 20>,
						<1 30 32 22 36 24 26 34 22 36 24 26 38>;
					paths-cck = <31 39 30 22>;
					paths-ofdm = <22 30 22 34>;
					paths-ofdm-bf = <0 30 22 26>;
					paths-ru =
						<1 22 30 24 36 32 24 26 20 36 30>,
						<1 24 38 20 16 30 20 30 24 38 24>,
						<1 30 30 22 30 24 38 20 16 30 30>,
						<1 23 30 22 30 24 38 20 16 30 30>,
						<3 22 30 24 36 32 24 26 20 36 30>;
					paths-ru-bf =
						<1 0 22 30 24 38 20 16 30 20 30>,
						<1 0 20 36 30 22 30 24 38 20 16>,
						<1 0 22 30 24 38 20 16 30 31 38>,
						<1 0 22 30 24 38 22 30 24 38 20>,
						<3 22 30 24 38 20 16 30 20 30 16>;
				};
				r52 {
					channels = <201 201>;
					rates-cck = <18 30 36 26>;
					rates-ofdm = <36 24 26 30 32 34 22 22>;
					rates-mcs = <4 36 24 26 30 32 34 22 22 24 26>;
					rates-ru =
						<4 36 24 26 30 32 34 22 22 24 26 30 32>,
						<1 34 22 28 28 30 32 22 26 28 32 34 36>,
						<1 36 34 32 28 26 22 32 30 28 28 22 34>,
						<1 22 36 22 26 24 22 30 22 26 30 32 28>;
					paths-cck = <24 37 23 29>;
					paths-ofdm = <26 24 32 22>;
					paths-ofdm-bf = <0 24 32 33>;
					paths-ru =
						<1 26 32 34 24 22 22 26 22 30 28>,
						<1 26 30 32 34 22 22 24 26 30 22>,
						<1 22 28 36 24 26 30 32 34 22 28>,
						<1 27 28 36 24 26 30 32 34 22 28>,
						<3 26 32 34 24 22 22 26 22 30 28>;
					paths-ru-bf =
						<1 0 36 24 26 30 32 34 22 22 24>,
						<1 0 22 30 28 36 24 26 30 32 34>,
						<1 0 36 24 26 30 32 34 22 35 30>,
						<1 0 36 24 26 30 36 24 26 30 32>,
						<3 36 24 26 30 32 34 22 22 24 34>;
				};
				r53 {
					channels = <213 213>;
					rates-cck = <22 26 24 30>;
					rates-ofdm = <36 24 26 30 32 34 22 22>;
					rates-mcs = <4 36 24 26 30 32 34 22 22 24 26>;
					rates-ru =
						<4 36 24 26 30 32 34 22 22 24 26 30 32>,
						<1 34 22 28 28 30 32 22 26 28 32 34 36>,
						<1 36 34 32 28 26 22 32 30 28 28 22 34>,
						<1 22 36 22 26 24 22 30 22 26 30 32 28>;
					paths-cck = <29 22 27 38>;
					paths-ofdm = <22 30 22 34>;
					paths-ofdm-bf = <0 30 22 31>;
					paths-ru =
						<1 26 32 34 24 22 22 26 22 30 28>,
						<1 26 30 32 34 22 22 24 26 30 22>,
						<1 22 28 36 24 26 30 32 34 22 28>,
						<1 29 28 36 24 26 30 32 34 22 28>,
						<3 26 32 34 24 22 22 26 22 30 28>;
					paths-ru-bf =
						<1 0 36 24 26 30 32 34 22 22 24>,
						<1 0 22 30 28 36 24 26 30 32 34>,
						<1 0 36 24 26 30 32 34 22 29 34>,
						<1 0 36 24 26 30 36 24 26 30 32>,
						<3 36 24 26 30 32 34 22 22 24 34>;
				};
				r54 {
					channels = <217 217>;
					rates-cck = <26 28 34 22>;
					rates-ofdm = <22 30 24 38 20 16 30 36>;
					rates-mcs = <4 22 30 24 38 20 16 30 36 30 24>;
					rates-ru =
						<4 22 30 24 38 20 16 30 36 30 24 38 20>,
						<1 22 24 26 28 30 32 34 36 38 24 30 26>,
						<1 26 30 24 38 36 34 32 30 28 26 24 22>,
						<1 20 22 24 30 36 22 32 34 22 24 26 28>;
					paths-cck = <35 26 35 31>;
					paths-ofdm = <26 24 32 22>;
					paths-ofdm-bf = <0 24 32 20>;
					paths-ru =
						<1 22 30 24 36 32 24 26 20 36 30>,
						<1 24 38 20 16 30 36 30 24 38 24>,
						<1 30 30 22 30 24 38 20 16 30 30>,
						<1 20 30 22 30 24 38 20 16 30 30>,
						<3 22 30 24 36 32 24 26 20 36 30>;
					paths-ru-bf =
						<1 0 22 30 24 38 20 16 30 36 30>,
						<1 0 20 36 30 22 30 24 38 20 16>,
						<1 0 22 30 24 38 20 16 30 22 29>,
						<1 0 22 30 24 38 22 30 24 38 20>,
						<3 22 30 24 38 20 16 30 36 30 16>;
				};
				r55 {
					channels =
						<221 221>,
						<233 233>;
					rates-cck = <18 30 36 26>;
					rates-ofdm = <36 24 26 30 32 34 22 20>;
					rates-mcs = <4 36 24 26 30 32 34 22 20 24 26>;
					rates-ru =
						<4 36 24 26 30 32 34 22 20 24 26 30 32>,
						<1 20 28 22 36 32 18 28 34 26 22 36 26>,
						<1 26 36 22 26 34 28 18 32 36 22 28 20>,
						<1 30 32 22 36 24 26 34 22 36 24 26 38>;
					paths-cck = <22 33 29 34>;
					paths-ofdm = <20 36 34 24>;
					paths-ofdm-bf = <0 36 34 27>;
					paths-ru =
						<1 26 32 34 24 22 22 26 22 30 28>,
						<1 26 30 32 34 22 20 24 26 30 22>,
						<1 22 28 36 24 26 30 32 34 22 28>,
						<1 27 28 36 24 26 30 32 34 22 28>,
						<3 26 32 34 24 22 22 26 22 30 28>;
					paths-ru-bf =
						<1 0 36 24 26 30 32 34 22 20 24>,
						<1 0 22 30 28 36 24 26 30 32 34>,
						<1 0 36 24 26 30 32 34 22 27 23>,
						<1 0 36 24 26 30 36 24 26 30 32>,
						<3 36 24 26 30 32 34 22 20 24 34>;
				};
				r56 {
					channels = <225 225>;
					rates-cck = <16 18 20 22>;
					rates-ofdm = <24 26 28 32 36 22 24 22>;
					rates-mcs = <4 24 26 28 32 36 22 24 22 26 28>;
					rates-ru =
						<4 24 26 28 32 36 22 24 22 26 28 32 36>,
						<1 34 22 28 28 30 32 22 26 28 32 34 36>,
						<1 36 34 32 28 26 22 32 30 28 28 22 34>,
						<1 22 36 22 26 24 22 30 22 26 30 32 28>;
					paths-cck = <33 38 23 36>;
					paths-ofdm = <22 30 22 34>;
					paths-ofdm-bf = <0 30 22 25>;
					paths-ru =
						<1 24 26 28 30 32 22 26 36 24 22>,
						<1 28 32 36 22 24 22 26 28 32 22>,
						<1 24 22 24 26 28 32 36 22 24 22>,
						<1 34 22 24 26 28 32 36 22 24 22>,
						<3 24 26 28 30 32 22 26 36 24 22>;
					paths-ru-bf =
						<1 0 24 26 28 32 36 22 24 22 26>,
						<1 0 36 24 22 24 26 28 32 36 22>,
						<1 0 24 26 28 32 36 22 24 35 24>,
						<1 0 24 26 28 32 24 26 28 32 36>,
						<3 24 26 28 32 36 22 24 22 26 22>;
				};
				r57 {
					channels = <229 229>;
					rates-cck = <26 24 22 30>;
					rates-ofdm = <22 30 24 38 20 16 30 36>;
					rates-mcs = <4 22 30 24 38 20 16 30 36 30 24>;
					rates-ru =
						<4 22 30 24 38 20 16 30 36 30 24 38 20>,
						<1 22 24 26 28 30 32 34 36 38 24 30 26>,
						<1 26 30 24 38 36 34 32 30 28 26 24 22>,
						<1 20 22 24 30 36 22 32 34 22 24 26 28>;
					paths-cck = <31 39 30 22>;
					paths-ofdm = <26 24 32 22>;
					paths-ofdm-bf = <0 24 32 38>;
					paths-ru =
						<1 22 30 24 36 32 24 26 20 36 30>,
						<1 24 38 20 16 30 36 30 24 38 24>,
						<1 30 30 22 30 24 38 20 16 30 30>,
						<1 34 30 22 30 24 38 20 16 30 30>,
						<3 22 30 24 36 32 24 26 20 36 30>;
					paths-ru-bf =
						<1 0 22 30 24 38 20 16 30 36 30>,
						<1 0 20 36 30 22 30 24 38 20 16>,
						<1 0 22 30 24 38 20 16 30 36 21>,
						<1 0 22 30 24 38 22 30 24 38 20>,
						<3 22 30 24 38 20 16 30 36 30 16>;
				};
			};
		};
	};
};

&pio {
	spi_flash_pins: spi-flash-pins-33-to-38 {
		mux {
			function = "flash";
			groups = "spi0", "spi0_wp_hold";
		};
		conf-pu {
			pins = "SPI2_CS", "SPI2_HOLD", "SPI2_WP";
			drive-strength = <MTK_DRIVE_8mA>;
			bias-pull-up = <MTK_PUPD_SET_R1R0_11>;
		};
		conf-pd {
			pins = "SPI2_CLK", "SPI2_MOSI", "SPI2_MISO";
			drive-strength = <MTK_DRIVE_8mA>;
			bias-pull-down = <MTK_PUPD_SET_R1R0_11>;
		};
	};

	wf_2g_5g_pins: wf_2g_5g-pins {
		mux {
			function = "wifi";
			groups = "wf_2g", "wf_5g";
		};
		conf {
			pins = "WF0_HB1", "WF0_HB2", "WF0_HB3", "WF0_HB4",
			       "WF0_HB0", "WF0_HB0_B", "WF0_HB5", "WF0_HB6",
			       "WF0_HB7", "WF0_HB8", "WF0_HB9", "WF0_HB10",
			       "WF0_TOP_CLK", "WF0_TOP_DATA", "WF1_HB1",
			       "WF1_HB2", "WF1_HB3", "WF1_HB4", "WF1_HB0",
			       "WF1_HB5", "WF1_HB6", "WF1_HB7", "WF1_HB8",
			       "WF1_TOP_CLK", "WF1_TOP_DATA";
			drive-strength = <MTK_DRIVE_4mA>;
		};
	};

	wf_dbdc_pins: wf_dbdc-pins {
		mux {
			function = "wifi";
			groups = "wf_dbdc";
		};
		conf {
			pins = "WF0_HB1", "WF0_HB2", "WF0_HB3", "WF0_HB4",
			       "WF0_HB0", "WF0_HB0_B", "WF0_HB5", "WF0_HB6",
			       "WF0_HB7", "WF0_HB8", "WF0_HB9", "WF0_HB10",
			       "WF0_TOP_CLK", "WF0_TOP_DATA", "WF1_HB1",
			       "WF1_HB2", "WF1_HB3", "WF1_HB4", "WF1_HB0",
			       "WF1_HB5", "WF1_HB6", "WF1_HB7", "WF1_HB8",
			       "WF1_TOP_CLK", "WF1_TOP_DATA";
			drive-strength = <MTK_DRIVE_4mA>;
		};
	};
};

